VERSION "FL_CH_CANFD"

NS_ :

BS_:

BU_: ACU ADCC APA EGS EPS ESP FLZCU ONEBOX RXCU

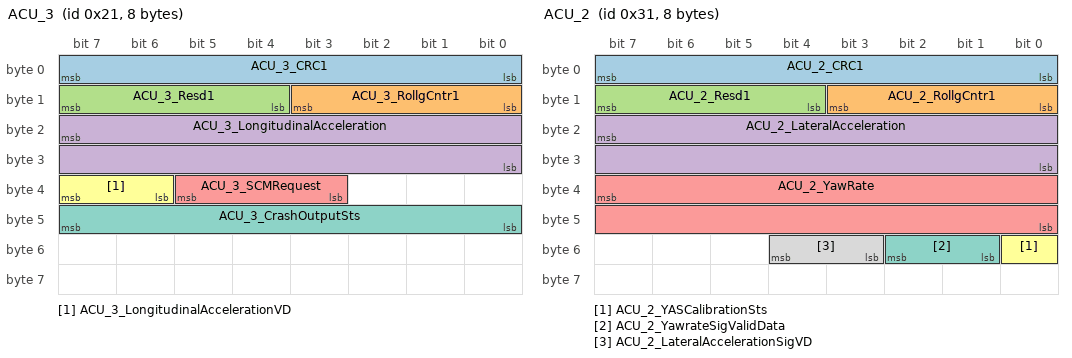
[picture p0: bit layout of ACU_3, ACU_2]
BO_ 33 ACU_3: 8 ACU
 SG_ ACU_3_CRC1 : 7|8@0+ (1,0) [0|255] "" RXCU
 SG_ ACU_3_RollgCntr1 : 11|4@0+ (1,0) [0|14] "" RXCU
 SG_ ACU_3_Resd1 : 15|4@0+ (1,0) [0|15] "" RXCU
 SG_ ACU_3_LongitudinalAcceleration : 23|16@0+ (0.001,-2) [-2|2] "g" RXCU
 SG_ ACU_3_SCMRequest : 37|3@0+ (1,0) [0|7] "" RXCU
 SG_ ACU_3_LongitudinalAccelerationVD : 39|2@0+ (1,0) [0|3] "" RXCU
 SG_ ACU_3_CrashOutputSts : 47|8@0+ (1,0) [0|255] "" RXCU

BO_ 49 ACU_2: 8 ACU
 SG_ ACU_2_CRC1 : 7|8@0+ (1,0) [0|255] "" RXCU
 SG_ ACU_2_RollgCntr1 : 11|4@0+ (1,0) [0|14] "" RXCU
 SG_ ACU_2_Resd1 : 15|4@0+ (1,0) [0|15] "" RXCU
 SG_ ACU_2_LateralAcceleration : 23|16@0+ (0.001,-2) [-2|2] "g" RXCU
 SG_ ACU_2_YawRate : 39|16@0+ (0.01,-180) [-180|180] "deg/sec" RXCU
 SG_ ACU_2_YASCalibrationSts : 48|1@0+ (1,0) [0|1] "" RXCU
 SG_ ACU_2_YawrateSigValidData : 50|2@0+ (1,0) [0|3] "" RXCU
 SG_ ACU_2_LateralAccelerationSigVD : 52|2@0+ (1,0) [0|3] "" RXCU

BO_ 56 VCU_COM_10: 16 RXCU
 SG_ VCU_10_CRC : 7|8@0+ (1,0) [0|255] "" ADCC,APA,FLZCU,ONEBOX
 SG_ VCU_10_RollgCntr : 11|4@0+ (1,0) [0|14] "" ADCC,APA,FLZCU,ONEBOX
 SG_ VCU_10_Resd : 15|4@0+ (1,0) [0|15] "" ADCC,APA,FLZCU,ONEBOX
 SG_ VCU_10_ShiftInProgress : 16|1@0+ (1,0) [0|1] "" ADCC,APA,FLZCU,ONEBOX
 SG_ VCU_10_ShiftInProgressValidData : 17|1@0+ (1,0) [0|1] "" ADCC,APA,FLZCU,ONEBOX
 SG_ VCU_10_TargetGear : 20|3@0+ (1,0) [0|7] "" ADCC,APA,FLZCU,ONEBOX
 SG_ VCU_10_ActualGear : 23|3@0+ (1,0) [0|7] "" ADCC,APA,FLZCU,ONEBOX
 SG_ VCU_10_TargetGearValidData : 28|1@0+ (1,0) [0|1] "" ADCC,APA,FLZCU,ONEBOX
 SG_ VCU_10_ActualGearValidData : 29|1@0+ (1,0) [0|1] "" ADCC,APA,FLZCU,ONEBOX
 SG_ VCU_10_BrakePedalStsValidData : 30|1@0+ (1,0) [0|1] "" ADCC,APA,FLZCU
 SG_ VCU_10_BrakePedalSts : 31|1@0+ (1,0) [0|1] "" ADCC,APA,FLZCU
 SG_ VCU_10_TowingMode : 49|2@0+ (1,0) [0|3] "" ADCC,APA,FLZCU,ONEBOX
 SG_ HCU_TCUR_GearShiftProgFlag : 63|2@0+ (1,0) [0|3] "" FLZCU,ONEBOX
 SG_ VCU_10_CRC2 : 71|8@0+ (1,0) [0|255] "" FLZCU
 SG_ VCU_10_RollgCntr2 : 75|4@0+ (1,0) [0|14] "" FLZCU
 SG_ VCU_10_Resd2 : 79|4@0+ (1,0) [0|15] "" FLZCU

BO_ 59 VCU_ONEBOX_11: 64 RXCU
 SG_ VCU_11_CRC1 : 7|8@0+ (1,0) [0|255] "" ADCC,APA,EPS,FLZCU,ONEBOX
 SG_ VCU_11_RollgCntr1 : 11|4@0+ (1,0) [0|14] "" ADCC,APA,EPS,FLZCU,ONEBOX
 SG_ VCU_11_Resd1 : 15|4@0+ (1,0) [0|15] "" ADCC,APA,EPS,FLZCU,ONEBOX
 SG_ VCU_11_IndicatedDriverReqWhlTqFA : 23|16@0+ (1,-32768) [-32768|32767] "NM" ADCC,APA,EPS,FLZCU,ONEBOX
 SG_ VCU_11_ActWheelTorqueFA : 39|16@0+ (1,-32768) [-32768|32767] "NM" ADCC,APA,EPS,FLZCU,ONEBOX
 SG_ VCU_11_ActWheelSpdFA : 55|16@0+ (1,-32767) [-32767|32767] "RPM" ADCC,APA,EPS,FLZCU,ONEBOX
 SG_ VCU_11_CRC2 : 71|8@0+ (1,0) [0|255] "" ADCC,APA,EPS,FLZCU,ONEBOX
 SG_ VCU_11_RollgCntr2 : 75|4@0+ (1,0) [0|14] "" ADCC,APA,EPS,FLZCU,ONEBOX
 SG_ VCU_11_Resd2 : 79|4@0+ (1,0) [0|15] "" ADCC,APA,EPS,FLZCU,ONEBOX
 SG_ VCU_11_IndcdDriverReqWhlTqStsFA : 80|1@0+ (1,0) [0|1] "" ADCC,APA,FLZCU,ONEBOX
 SG_ VCU_11_ActWheelTorqueStsFA : 82|2@0+ (1,0) [0|3] "" ADCC,APA,EPS,FLZCU,ONEBOX
 SG_ VCU_11_ActWheelSpdStsFA : 83|1@0+ (1,0) [0|1] "" ADCC,APA,EPS,FLZCU,ONEBOX
 SG_ VCU_11_MotorReadyFMCU : 84|1@0+ (1,0) [0|1] "" ADCC,APA,FLZCU,ONEBOX
 SG_ VCU_11_IndicatedDriverReqWhlTqRA : 95|16@0+ (1,-32768) [-32768|32767] "NM" ADCC,APA,FLZCU,ONEBOX
 SG_ VCU_11_ActWheelTorqueRA : 111|16@0+ (1,-32768) [-32768|32767] "NM" ADCC,APA,FLZCU,ONEBOX
 SG_ VCU_11_CRC3 : 135|8@0+ (1,0) [0|255] "" ADCC,APA,FLZCU,ONEBOX
 SG_ VCU_11_RollgCntr3 : 139|4@0+ (1,0) [0|14] "" ADCC,APA,FLZCU,ONEBOX
 SG_ VCU_11_Resd3 : 143|4@0+ (1,0) [0|15] "" ADCC,APA,FLZCU,ONEBOX
 SG_ VCU_11_ActWheelSpdRA : 151|16@0+ (1,-32767) [-32767|32767] "RPM" ADCC,APA,FLZCU,ONEBOX
 SG_ VCU_11_IndcdDriverReqWhlTqStsRA : 160|1@0+ (1,0) [0|1] "" ADCC,APA,FLZCU,ONEBOX
 SG_ VCU_11_ActWheelTorqueStsRA : 162|2@0+ (1,0) [0|3] "" ADCC,APA,FLZCU,ONEBOX
 SG_ VCU_11_MotorReadyRMCU : 163|1@0+ (1,0) [0|1] "" ADCC,APA,FLZCU,ONEBOX
 SG_ VCU_11_ActWheelSpdStsRA : 164|1@0+ (1,0) [0|1] "" ADCC,APA,FLZCU,ONEBOX
 SG_ VCU_11_MbRegenMaxWheel : 175|16@0+ (1,-32768) [-32768|32767] "NM" ADCC,APA,FLZCU,ONEBOX
 SG_ VCU_11_CRC4 : 199|8@0+ (1,0) [0|255] "" ADCC,APA,FLZCU,ONEBOX
 SG_ VCU_11_RollgCntr4 : 203|4@0+ (1,0) [0|14] "" ADCC,APA,FLZCU,ONEBOX
 SG_ VCU_11_Resd4 : 207|4@0+ (1,0) [0|15] "" ADCC,APA,FLZCU,ONEBOX
 SG_ VCU_11_MbRegenWheel : 215|16@0+ (1,-32768) [-32768|32767] "NM" ADCC,APA,FLZCU,ONEBOX
 SG_ VCU_11_MbRegenMaxWheelQualifier : 225|2@0+ (1,0) [0|3] "" ADCC,APA,FLZCU,ONEBOX
 SG_ VCU_11_MbRegenWheelQualifier : 227|2@0+ (1,0) [0|3] "" ADCC,APA,FLZCU,ONEBOX
 SG_ VCU_11_EPBReq : 229|2@0+ (1,0) [0|3] "" ADCC,APA,FLZCU,ONEBOX
 SG_ VCU_11_GasPedalPosInvalidData : 230|1@0+ (1,0) [0|1] "" ADCC,APA,FLZCU,ONEBOX
 SG_ VCU_11_AcceleratorPosRawIVD : 231|1@0+ (1,0) [0|1] "" ADCC,APA,FLZCU,ONEBOX
 SG_ VCU_11_GasPedalPosition : 239|10@0+ (0.1,0) [0|100] "%" ADCC,APA,FLZCU,ONEBOX
 SG_ VCU_11_AcceleratorPosRaw : 245|10@0+ (0.1,0) [0|100] "%" ADCC,APA,FLZCU,ONEBOX
 SG_ VCU_11_EPBReqValid : 251|1@0+ (1,0) [0|1] "" ADCC,APA,FLZCU,ONEBOX
 SG_ VCU_11_CRC5 : 263|8@0+ (1,0) [0|255] "" ADCC,APA,FLZCU
 SG_ VCU_11_RollgCntr5 : 267|4@0+ (1,0) [0|14] "" ADCC,APA,FLZCU
 SG_ VCU_11_Resd5 : 271|4@0+ (1,0) [0|15] "" ADCC,APA,FLZCU
 SG_ VCU_11_CoastRegenTargetWheelFA : 279|16@0+ (1,-32768) [-32768|32767] "NM" ADCC,APA,FLZCU,ONEBOX
 SG_ VCU_11_CoastRegenTargetWheelFAQ : 295|2@0+ (1,0) [0|3] "" ADCC,APA,FLZCU,ONEBOX
 SG_ VCU_11_CoastRegenTargetWheelRA : 303|16@0+ (1,-32768) [-32768|32767] "NM" ADCC,APA,FLZCU,ONEBOX
 SG_ VCU_11_CoastRegenTargetWheelRAQ : 319|2@0+ (1,0) [0|3] "" ADCC,APA,FLZCU,ONEBOX
 SG_ VCU_11_CRC6 : 327|8@0+ (1,0) [0|255] "" ADCC,APA,FLZCU
 SG_ VCU_11_RollgCntr6 : 331|4@0+ (1,0) [0|14] "" ADCC,APA,FLZCU
 SG_ VCU_11_Resd6 : 335|4@0+ (1,0) [0|15] "" ADCC,APA,FLZCU
 SG_ VCU_11_MaxWheelTorqueFA : 343|16@0+ (1,-32768) [-32768|32767] "NM" ADCC,APA,FLZCU,ONEBOX
 SG_ VCU_11_MaxWheelTorqueRA : 359|16@0+ (1,-32768) [-32768|32767] "NM" ADCC,APA,FLZCU,ONEBOX
 SG_ HCU_11_iTASRearTorque_Max : 375|16@0+ (1,-12000) [-12000|12000] "Nm" APA,FLZCU,ONEBOX
 SG_ VCU_11_CRC7 : 391|8@0+ (1,0) [0|255] "" ADCC,APA,FLZCU
 SG_ VCU_11_RollgCntr7 : 395|4@0+ (1,0) [0|14] "" ADCC,APA,FLZCU
 SG_ VCU_11_Resd7 : 399|4@0+ (1,0) [0|15] "" ADCC,APA,FLZCU
 SG_ VCU_11_OPDHoldRequest : 405|2@0+ (1,0) [0|3] "" ADCC,APA,FLZCU,ONEBOX
 SG_ VCU_11_OPDHydBrkCompenRqSts : 406|1@0+ (1,0) [0|1] "" ADCC,APA,FLZCU,ONEBOX
 SG_ VCU_11_OnePedalstatus : 407|1@0+ (1,0) [0|1] "" ADCC,APA,FLZCU,ONEBOX
 SG_ VCU_11_OPDHydBrkCompenRqTq : 415|16@0+ (1,-65535) [-65535|0] "NM" ADCC,APA,FLZCU,ONEBOX
 SG_ HCU_11_RearWheelDir : 426|2@0+ (1,0) [0|3] "" FLZCU,ONEBOX
 SG_ VCU_11_DrivingModReq : 431|5@0+ (1,0) [0|31] "" FLZCU,ONEBOX
 SG_ HCU_11_iTASFrontTorque_Max : 439|16@0+ (1,-12000) [-12000|12000] "Nm" FLZCU,ONEBOX
 SG_ VCU_11_CRC8 : 455|8@0+ (1,0) [0|255] "" ADCC,FLZCU
 SG_ VCU_11_RollgCntr8 : 459|4@0+ (1,0) [0|14] "" ADCC,FLZCU
 SG_ VCU_11_Resd8 : 463|4@0+ (1,0) [0|15] "" ADCC,FLZCU

BO_ 75 VCU_ADCC_12: 24 RXCU
 SG_ VCU_12_CRC1 : 7|8@0+ (1,0) [0|255] "" ADCC,APA,FLZCU,ONEBOX
 SG_ VCU_12_RollgCntr1 : 11|4@0+ (1,0) [0|14] "" ADCC,APA,FLZCU,ONEBOX
 SG_ VCU_12_Resd1 : 15|4@0+ (1,0) [0|15] "" ADCC,APA,FLZCU,ONEBOX
 SG_ VCU_12_DriverTorqueDesired : 23|16@0+ (1,-32768) [-32768|32767] "NM" ADCC,APA,FLZCU
 SG_ VCU_12_VehWhlActTq : 39|16@0+ (1,-32768) [-32768|32767] "NM" ADCC,APA,FLZCU,ONEBOX
 SG_ VCU_12_VehWhlActTqVld : 48|1@0+ (1,0) [0|1] "" ADCC,APA,FLZCU
 SG_ VCU_12_DrvrGearIntervention : 49|1@0+ (1,0) [0|1] "" ADCC,APA,FLZCU
 SG_ VCU_12_PtTqActvSts : 50|1@0+ (1,0) [0|1] "" ADCC,APA,FLZCU
 SG_ VCU_12_PtTqAvl : 52|2@0+ (1,0) [0|3] "" ADCC,APA,FLZCU
 SG_ VCU_12_DrvrAccrPedlOvrd : 53|1@0+ (1,0) [0|1] "" ADCC,APA,FLZCU
 SG_ VCU_12_DrvrAccrPedlOvrdInVD : 54|1@0+ (1,0) [0|1] "" ADCC,APA,FLZCU
 SG_ VCU_12_CRC2 : 71|8@0+ (1,0) [0|255] "" ADCC,APA,FLZCU
 SG_ VCU_12_RollgCntr2 : 75|4@0+ (1,0) [0|14] "" ADCC,APA,FLZCU
 SG_ VCU_12_Resd2 : 79|4@0+ (1,0) [0|15] "" ADCC,APA,FLZCU
 SG_ VCU_12_PtTqMax : 87|16@0+ (1,-32768) [-32768|32767] "NM" ADCC,APA,FLZCU
 SG_ HCU_12_PtTqMinVld : 96|1@0+ (1,0) [0|1] "" ADCC,APA,FLZCU
 SG_ TargetGearTransInp : 100|3@0+ (1,0) [0|7] "" ADCC,FLZCU
 SG_ VCU_12_GasPedalInhabition : 101|1@0+ (1,0) [0|1] "" ADCC,APA,FLZCU
 SG_ VCU_12_PtTqMaxVld : 103|1@0+ (1,0) [0|1] "" ADCC,APA,FLZCU
 SG_ HCU_12_PtTqMin : 111|16@0+ (1,-32768) [-32768|32767] "NM" ADCC,APA,FLZCU
 SG_ HCU_26_TargetGearEM2 : 127|2@0+ (1,0) [0|3] "" ADCC,FLZCU
 SG_ VCU_12_CRC3 : 135|8@0+ (1,0) [0|255] "" ADCC,APA,FLZCU
 SG_ VCU_12_RollgCntr3 : 139|4@0+ (1,0) [0|14] "" ADCC,APA,FLZCU
 SG_ VCU_12_Resd3 : 143|4@0+ (1,0) [0|15] "" ADCC,APA,FLZCU
 SG_ VCU_12_VehWhlActTqADS : 151|16@0+ (1,0) [0|65535] "NM" ADCC,APA,FLZCU
 SG_ VCU_12_VehWhlActTqADSVld : 167|1@0+ (1,0) [0|1] "" ADCC,APA,FLZCU

BO_ 152 ONEBOX_1: 24 ESP
 SG_ ONEBOX_1_CRC1 : 7|8@0+ (1,0) [0|255] "" RXCU
 SG_ ONEBOX_1_RollgCntr1 : 11|4@0+ (1,0) [0|14] "" RXCU
 SG_ ONEBOX_1_Resd1 : 15|4@0+ (1,0) [0|15] "" RXCU
 SG_ ABS_ESP_1_VehicleSpeedVSOSig : 23|13@0+ (0.0625,0) [0|511.875] "km/h" RXCU
 SG_ ABS_ESP_1_ABSFailSts : 24|1@0+ (1,0) [0|1] "" RXCU
 SG_ ABS_ESP_1_EBDFailSts : 25|1@0+ (1,0) [0|1] "" RXCU
 SG_ ESP1_VehicleSpeedVSOSigValidData : 26|1@0+ (1,0) [0|1] "" RXCU
 SG_ ONEBOX_1_IPB_SimulatorPressure : 39|10@0+ (1,0) [0|1022] "Bar" RXCU
 SG_ IPB_SimulatorPressureSts : 40|1@0+ (1,0) [0|1] "" RXCU
 SG_ ABS_ESP_1_ABSActive : 41|1@0+ (1,0) [0|1] "" RXCU
 SG_ ABS_ESP_1_VDCFailSts : 42|1@0+ (1,0) [0|1] "" RXCU
 SG_ ABS_ESP_1_VDCActive : 43|1@0+ (1,0) [0|1] "" RXCU
 SG_ ABS_ESP_1_TCSFailSts : 44|1@0+ (1,0) [0|1] "" RXCU
 SG_ ABS_ESP_1_TCSActive : 45|1@0+ (1,0) [0|1] "" RXCU
 SG_ BrakeSystemType : 48|1@0+ (1,0) [0|1] "" RXCU
 SG_ ABS_ESP_1_HHCFailSts : 49|1@0+ (1,0) [0|1] "" RXCU
 SG_ ONEBOX_1_HHCActive : 50|1@0+ (1,0) [0|1] "" RXCU
 SG_ ABS_ESP_1_HDCCtrlSts : 52|2@0+ (1,0) [0|3] "" RXCU
 SG_ ABS_ESP_1_HDCFailSts : 53|1@0+ (1,0) [0|1] "" RXCU
 SG_ ONEBOX_1_HLRequest : 54|1@0+ (1,0) [0|1] "" RXCU
 SG_ ABS_ESP_1_ESPSwitchStatus : 55|1@0+ (1,0) [0|1] "" RXCU
 SG_ ONEBOX_1_BLRequestController : 56|1@0+ (1,0) [0|1] "" RXCU
 SG_ SwitchOffCruiseControl : 57|1@0+ (1,0) [0|1] "" RXCU
 SG_ ONEBOX_1_CRC2 : 71|8@0+ (1,0) [0|255] "" RXCU
 SG_ ONEBOX_1_RollgCntr2 : 75|4@0+ (1,0) [0|14] "" RXCU
 SG_ ONEBOX_1_Resd2 : 79|4@0+ (1,0) [0|15] "" RXCU
 SG_ IPB_1_MbRegenTargetWheel : 87|16@0+ (1,-32768) [-32768|32767] "NM" RXCU
 SG_ IPB_1_MbRegenTargetWheelQ : 97|2@0+ (1,0) [0|3] "" RXCU
 SG_ ONEBOX_1_AEBdecActive : 98|1@0+ (1,0) [0|1] "" RXCU
 SG_ ONEBOX_1_AEBdecAvailable : 99|1@0+ (1,0) [0|1] "" RXCU
 SG_ ONEBOX_1_CDPActive : 100|1@0+ (1,0) [0|1] "" RXCU
 SG_ Reserve_EPBStatus : 103|3@0+ (1,0) [0|7] "" RXCU
 SG_ ONEBOX_1_CDPFailSts : 104|1@0+ (1,0) [0|1] "" RXCU
 SG_ ONEBOX_1_CRC3 : 135|8@0+ (1,0) [0|255] "" RXCU
 SG_ ONEBOX_1_RollgCntr3 : 139|4@0+ (1,0) [0|14] "" RXCU
 SG_ ONEBOX_1_Resd3 : 143|4@0+ (1,0) [0|15] "" RXCU

BO_ 168 ONEBOX_2: 24 ESP
 SG_ ONEBOX_2_CRC1 : 7|8@0+ (1,0) [0|255] "" RXCU
 SG_ ONEBOX_2_RollgCntr1 : 11|4@0+ (1,0) [0|14] "" RXCU
 SG_ ONEBOX_2_Resd1 : 15|4@0+ (1,0) [0|15] "" RXCU
 SG_ LHFWheelSpeed_0A8h : 23|13@0+ (0.0625,0) [0|511.875] "km/h" RXCU
 SG_ LHFWheelSpeedValidData_0A8h : 26|1@0+ (1,0) [0|1] "" RXCU
 SG_ RHFWheelSpeed_0A8h : 39|13@0+ (0.0625,0) [0|511.875] "km/h" RXCU
 SG_ RHFWheelSpeedValidData_0A8h : 42|1@0+ (1,0) [0|1] "" RXCU
 SG_ LHRWheelSpeed_0A8h : 55|13@0+ (0.0625,0) [0|511.875] "km/h" RXCU
 SG_ LHRWheelSpeedValidData_0A8h : 58|1@0+ (1,0) [0|1] "" RXCU
 SG_ ONEBOX_2_CRC2 : 71|8@0+ (1,0) [0|255] "" RXCU
 SG_ ONEBOX_2_RollgCntr2 : 75|4@0+ (1,0) [0|14] "" RXCU
 SG_ ONEBOX_2_Resd2 : 79|4@0+ (1,0) [0|15] "" RXCU
 SG_ RHRWheelSpeed_0A8h : 87|13@0+ (0.0625,0) [0|511.875] "km/h" RXCU
 SG_ RHRWheelSpeedValidData_0A8h : 90|1@0+ (1,0) [0|1] "" RXCU
 SG_ LHFWheelSpeedRPM : 103|16@0+ (0.0625,0) [0|4095.875] "rpm" RXCU
 SG_ RHFWheelSpeedRPM : 119|16@0+ (0.0625,0) [0|4095.875] "rpm" RXCU
 SG_ ONEBOX_2_CRC3 : 135|8@0+ (1,0) [0|255] "" RXCU
 SG_ ONEBOX_2_RollgCntr3 : 139|4@0+ (1,0) [0|14] "" RXCU
 SG_ ONEBOX_2_Resd3 : 143|4@0+ (1,0) [0|15] "" RXCU
 SG_ LHRWheelSpeedRPM_0A8h : 151|16@0+ (0.0625,0) [0|4095.875] "rpm" RXCU
 SG_ RHRWheelSpeedRPM_0A8h : 167|16@0+ (0.0625,0) [0|4095.875] "rpm" RXCU
 SG_ RHFWheelSpeedRPMValidData : 176|1@0+ (1,0) [0|1] "" RXCU
 SG_ LHFWheelSpeedRPMValidData : 177|1@0+ (1,0) [0|1] "" RXCU
 SG_ RHFWheelDriveDirection_0A8h : 180|3@0+ (1,0) [0|7] "" RXCU
 SG_ LHFWheelDriveDirection_0A8h : 183|3@0+ (1,0) [0|7] "" RXCU
 SG_ RHRWheelSpeedRPMValidData : 184|1@0+ (1,0) [0|1] "" RXCU
 SG_ LHRWheelSpeedRPMValidData : 185|1@0+ (1,0) [0|1] "" RXCU
 SG_ RHRWheelDriveDirection_0A8h : 188|3@0+ (1,0) [0|7] "" RXCU
 SG_ LHRWheelDriveDirection_0A8h : 191|3@0+ (1,0) [0|7] "" RXCU

BO_ 265 ONEBOX_HW_109h: 48 ONEBOX
 SG_ ONEBOX_CRC1_109h : 7|8@0+ (1,0) [0|255] "" RXCU
 SG_ ONEBOX_RollgCntr1_109h : 11|4@0+ (1,0) [0|14] "" RXCU
 SG_ ONEBOX_Resd1_109h : 15|4@0+ (1,0) [0|15] "" RXCU
 SG_ ONEBOX_AebBrkTqAvl_109h : 16|1@0+ (1,0) [0|1] "" RXCU
 SG_ ONEBOX_AebBrkTqActv_109h : 31|1@0+ (1,0) [0|1] "" RXCU
 SG_ ONEBOX_DrvrBrkOvrdVld_109h : 40|1@0+ (1,0) [0|1] "" RXCU
 SG_ ONEBOX_DrvrBrkOvrd_109h : 42|2@0+ (1,0) [0|3] "" RXCU

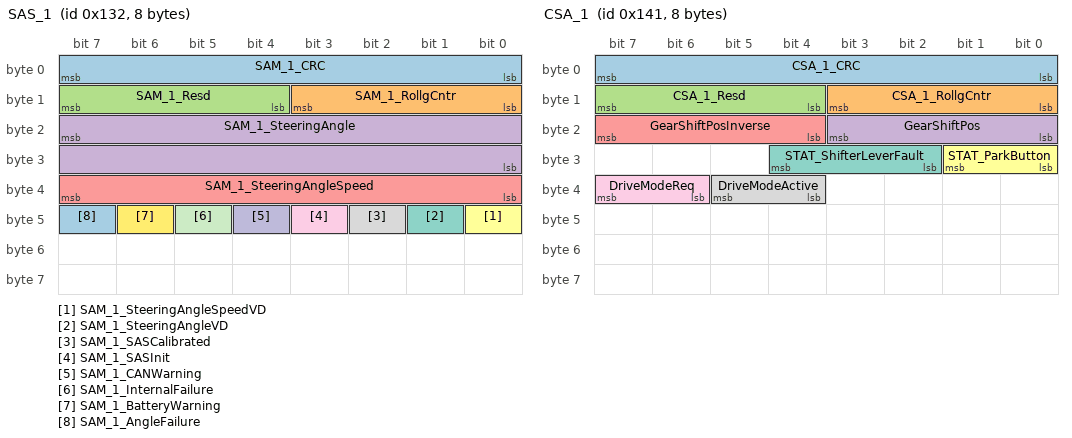
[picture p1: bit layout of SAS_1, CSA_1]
BO_ 306 SAS_1: 8 EPS
 SG_ SAM_1_CRC : 7|8@0+ (1,0) [0|255] "" RXCU
 SG_ SAM_1_RollgCntr : 11|4@0+ (1,0) [0|14] "" RXCU
 SG_ SAM_1_Resd : 15|4@0+ (1,0) [0|15] "" RXCU
 SG_ SAM_1_SteeringAngle : 23|16@0+ (0.0625,-2048) [-2048|2047.875] "deg" RXCU
 SG_ SAM_1_SteeringAngleSpeed : 39|8@0+ (4,0) [0|1016] "deg/Sec" RXCU
 SG_ SAM_1_SteeringAngleSpeedVD : 40|1@0+ (1,0) [0|1] "" RXCU
 SG_ SAM_1_SteeringAngleVD : 41|1@0+ (1,0) [0|1] "" RXCU
 SG_ SAM_1_SASCalibrated : 42|1@0+ (1,0) [0|1] "" RXCU
 SG_ SAM_1_SASInit : 43|1@0+ (1,0) [0|1] "" RXCU
 SG_ SAM_1_CANWarning : 44|1@0+ (1,0) [0|1] "" RXCU
 SG_ SAM_1_InternalFailure : 45|1@0+ (1,0) [0|1] "" RXCU
 SG_ SAM_1_BatteryWarning : 46|1@0+ (1,0) [0|1] "" RXCU
 SG_ SAM_1_AngleFailure : 47|1@0+ (1,0) [0|1] "" RXCU

BO_ 321 CSA_1: 8 EGS
 SG_ CSA_1_CRC : 7|8@0+ (1,0) [0|255] "" RXCU
 SG_ CSA_1_RollgCntr : 11|4@0+ (1,0) [0|14] "" RXCU
 SG_ CSA_1_Resd : 15|4@0+ (1,0) [0|15] "" RXCU
 SG_ GearShiftPos : 19|4@0+ (1,0) [0|15] "" RXCU
 SG_ GearShiftPosInverse : 23|4@0+ (1,0) [0|15] "" RXCU
 SG_ STAT_ParkButton : 25|2@0+ (1,0) [0|3] "" RXCU
 SG_ STAT_ShifterLeverFault : 28|3@0+ (1,0) [0|7] "" RXCU
 SG_ DriveModeActive : 37|2@0+ (1,0) [0|3] "" RXCU
 SG_ DriveModeReq : 39|2@0+ (1,0) [0|3] "" RXCU

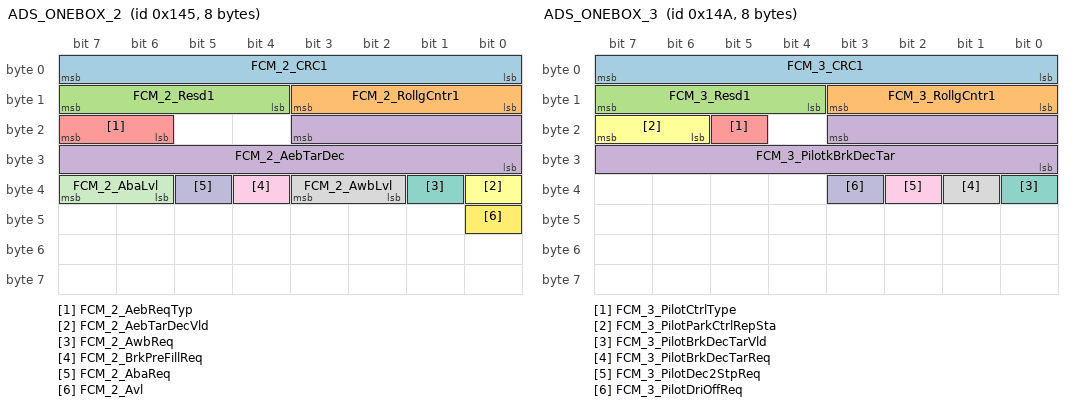
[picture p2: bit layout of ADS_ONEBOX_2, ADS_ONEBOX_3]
BO_ 325 ADS_ONEBOX_2: 8 ADCC
 SG_ FCM_2_CRC1 : 7|8@0+ (1,0) [0|255] "" RXCU
 SG_ FCM_2_RollgCntr1 : 11|4@0+ (1,0) [0|14] "" RXCU
 SG_ FCM_2_Resd1 : 15|4@0+ (1,0) [0|15] "" RXCU
 SG_ FCM_2_AebTarDec : 19|12@0+ (0.01,-20) [-20|0] "m/s2" RXCU
 SG_ FCM_2_AebReqTyp : 23|2@0+ (1,0) [0|3] "" RXCU
 SG_ FCM_2_AebTarDecVld : 32|1@0+ (1,0) [0|1] "" RXCU
 SG_ FCM_2_AwbReq : 33|1@0+ (1,0) [0|1] "" RXCU
 SG_ FCM_2_AwbLvl : 35|2@0+ (1,0) [0|3] "" RXCU
 SG_ FCM_2_BrkPreFillReq : 36|1@0+ (1,0) [0|1] "" RXCU
 SG_ FCM_2_AbaReq : 37|1@0+ (1,0) [0|1] "" RXCU
 SG_ FCM_2_AbaLvl : 39|2@0+ (1,0) [0|3] "" RXCU
 SG_ FCM_2_Avl : 40|1@0+ (1,0) [0|1] "" RXCU

BO_ 330 ADS_ONEBOX_3: 8 ADCC
 SG_ FCM_3_CRC1 : 7|8@0+ (1,0) [0|255] "" RXCU
 SG_ FCM_3_RollgCntr1 : 11|4@0+ (1,0) [0|14] "" RXCU
 SG_ FCM_3_Resd1 : 15|4@0+ (1,0) [0|15] "" RXCU
 SG_ FCM_3_PilotkBrkDecTar : 19|12@0+ (0.01,-20) [-20|20] "m/s2" RXCU
 SG_ FCM_3_PilotCtrlType : 21|1@0+ (1,0) [0|1] "" RXCU
 SG_ FCM_3_PilotParkCtrlRepSta : 23|2@0+ (1,0) [0|3] "" RXCU
 SG_ FCM_3_PilotBrkDecTarVld : 32|1@0+ (1,0) [0|1] "" RXCU
 SG_ FCM_3_PilotBrkDecTarReq : 33|1@0+ (1,0) [0|1] "" RXCU
 SG_ FCM_3_PilotDec2StpReq : 34|1@0+ (1,0) [0|1] "" RXCU
 SG_ FCM_3_PilotDriOffReq : 35|1@0+ (1,0) [0|1] "" RXCU

BO_ 335 ONEBOX_5: 24 ESP
 SG_ ONEBOX_5_CRC1 : 7|8@0+ (1,0) [0|255] "" RXCU
 SG_ ONEBOX_5_RollgCntr1 : 11|4@0+ (1,0) [0|14] "" RXCU
 SG_ ONEBOX_5_Resd1 : 15|4@0+ (1,0) [0|15] "" RXCU
 SG_ ONEBOX_5_PilotParkBrkDecCtlAvl : 16|1@0+ (1,0) [0|1] "" RXCU
 SG_ ONEBOX_5_PilotParkBrkDecActSts : 18|2@0+ (1,0) [0|3] "" RXCU
 SG_ ONEBOX_5_CddAdcActiveVehHld : 19|1@0+ (1,0) [0|1] "" RXCU
 SG_ ONEBOX_5_APCFailureSts : 23|4@0+ (1,0) [0|15] "" RXCU
 SG_ ONEBOX_5_APCStatus : 26|3@0+ (1,0) [0|7] "" RXCU
 SG_ ONEBOX_5_ApaAvl : 27|1@0+ (1,0) [0|1] "" RXCU
 SG_ ONEBOX_5_RpaAvl : 28|1@0+ (1,0) [0|1] "" RXCU
 SG_ ONEBOX_5_MebAvl : 29|1@0+ (1,0) [0|1] "" RXCU
 SG_ ONEBOX_5_CddApActiveVehHld : 30|1@0+ (1,0) [0|1] "" RXCU
 SG_ ONEBOX_5_SysBrkP : 39|10@0+ (1,0) [0|1022] "Bar" RXCU
 SG_ ONEBOX_5_SysBrkPVld : 40|1@0+ (1,0) [0|1] "" RXCU
 SG_ ONEBOX_5_AbpActSts : 41|1@0+ (1,0) [0|1] "" RXCU
 SG_ ONEBOX_5_AbpAvlSts : 42|1@0+ (1,0) [0|1] "" RXCU
 SG_ ONEBOX_5_AwbActSts : 43|1@0+ (1,0) [0|1] "" RXCU
 SG_ ONEBOX_5_AwbAvlSts : 44|1@0+ (1,0) [0|1] "" RXCU
 SG_ ONEBOX_5_AbaActSts : 45|1@0+ (1,0) [0|1] "" RXCU
 SG_ ONEBOX_5_AbaAvlSts : 48|1@0+ (1,0) [0|1] "" RXCU
 SG_ ONEBOX_5_AbaLvlSts : 50|2@0+ (1,0) [0|3] "" RXCU
 SG_ ONEBOX_5_CRC2 : 71|8@0+ (1,0) [0|255] "" RXCU
 SG_ ONEBOX_5_RollgCntr2 : 75|4@0+ (1,0) [0|14] "" RXCU
 SG_ ONEBOX_5_Resd2 : 79|4@0+ (1,0) [0|15] "" RXCU
 SG_ ONEBOX_5_OPDHydAvalible : 80|1@0+ (1,0) [0|1] "" RXCU
 SG_ ONEBOX_5_CoastRegenQualify_FA : 82|2@0+ (1,0) [0|3] "" RXCU
 SG_ ONEBOX_5_OPDHydBrkActvCompenTqVD : 83|1@0+ (1,0) [0|1] "" RXCU
 SG_ ONEBOX_5_OPDHoldStatus : 84|1@0+ (1,0) [0|1] "" RXCU
 SG_ ONEBOX_5_VehicleStandstillValid : 85|1@0+ (1,0) [0|1] "" RXCU
 SG_ ONEBOX_5_VehicleStandstill : 86|1@0+ (1,0) [0|1] "" RXCU
 SG_ ONEBOX_5_OPDHydBrkActvCompenTq : 95|16@0+ (1,-65535) [-65535|0] "NM" RXCU
 SG_ ONEBOX_5_OmpEngTorqReq : 111|16@0+ (1,-32768) [-32768|32767] "Nm" RXCU
 SG_ ONEBOX_5_OmpStatus : 125|2@0+ (1,0) [0|3] "" RXCU
 SG_ ONEBOX_5_OmpEngTorqReqEna : 127|2@0+ (1,0) [0|3] "" RXCU

BO_ 345 ADS_ONEBOX_1: 16 ADCC
 SG_ ADS_1_CRC1 : 7|8@0+ (1,0) [0|255] "" RXCU
 SG_ ADS_1_RollgCntr1 : 11|4@0+ (1,0) [0|14] "" RXCU
 SG_ ADS_1_Resd1 : 15|4@0+ (1,0) [0|15] "" RXCU
 SG_ ADS_1_PilotParkBrkDecTar : 19|12@0+ (0.01,-20) [-20|20] "m/s2" RXCU
 SG_ ADS_1_PilotParkCtrlType : 21|1@0+ (1,0) [0|1] "" RXCU
 SG_ ADS_1_PilotCtrlRepSta : 23|2@0+ (1,0) [0|3] "" RXCU
 SG_ ADS_1_PilotParkCtrlRepMod : 33|2@0+ (1,0) [0|3] "" RXCU
 SG_ ADS_1_PilotParkBrkDecTarVld : 34|1@0+ (1,0) [0|1] "" RXCU
 SG_ ADS_1_PilotParkBrkDecTarEnable : 35|1@0+ (1,0) [0|1] "" RXCU
 SG_ ADS_1_PilotParkDec2StpReq : 36|1@0+ (1,0) [0|1] "" RXCU
 SG_ ADS_1_PilotParkDriOffReq : 37|1@0+ (1,0) [0|1] "" RXCU
 SG_ ADS_1_StopDist : 47|16@0+ (1,0) [0|65535] "mm" RXCU
 SG_ ADS_1_ParkCtrlMod : 58|3@0+ (1,0) [0|7] "" RXCU
 SG_ ADS_1_PreFillReq : 59|1@0+ (1,0) [0|1] "" RXCU
 SG_ ADS_EPBCtrlReqValid : 60|1@0+ (1,0) [0|1] "" RXCU
 SG_ ADS_EPBCtrlReq : 62|2@0+ (1,0) [0|3] "" RXCU

BO_ 359 ADS_VCU_1: 16 ADCC
 SG_ ADS_VCU_1_CRC1 : 7|8@0+ (1,0) [0|255] "" RXCU
 SG_ ADS_VCU_1_RollgCntr1 : 11|4@0+ (1,0) [0|14] "" RXCU
 SG_ ADS_VCU_1_Resd1 : 15|4@0+ (1,0) [0|15] "" RXCU
 SG_ ADS_VCU_1_DrvTarTq : 23|16@0+ (1,-1000) [-1000|64535] "NM" RXCU
 SG_ ADS_VCU_1_DrvTarTqVld : 32|1@0+ (1,0) [0|1] "" RXCU
 SG_ ADS_VCU_1_DrvCtrlReq : 34|2@0+ (1,0) [0|3] "" RXCU
 SG_ ADS_VCU_1_CtrlReqMod : 36|2@0+ (1,0) [0|3] "" RXCU
 SG_ ADS_VCU_1_DrvTarTqEnable : 37|1@0+ (1,0) [0|1] "" RXCU
 SG_ ADS_VCU_1_AMAPRequest : 38|1@0+ (1,0) [0|1] "" RXCU
 SG_ ADS_VCU_1_AMAPRequestVld : 39|1@0+ (1,0) [0|1] "" RXCU
 SG_ ADS_VCU_1_ADCCAvl : 40|1@0+ (1,0) [0|1] "" RXCU
 SG_ ADS_VCU_1_AMAPTqLimitVld : 41|1@0+ (1,0) [0|1] "" RXCU
 SG_ FCM_FRM2_ACCStartStopInfo_167h : 61|2@0+ (1,0) [0|3] "" RXCU
 SG_ ADS_VCU_1_CRC2 : 71|8@0+ (1,0) [0|255] "" RXCU
 SG_ ADS_VCU_1_RollgCntr2 : 75|4@0+ (1,0) [0|14] "" RXCU
 SG_ ADS_VCU_1_Resd2 : 79|4@0+ (1,0) [0|15] "" RXCU
 SG_ ADS_VCU_1_TarGearReq : 82|3@0+ (1,0) [0|7] "" RXCU
 SG_ ADS_VCU_1_TarGearReqVld : 83|1@0+ (1,0) [0|1] "" RXCU
 SG_ ADS_VCU_1_GearCtrlEnable : 85|1@0+ (1,0) [0|1] "" RXCU
 SG_ ADS_VCU_1_RpaPTReadyReq : 86|1@0+ (1,0) [0|1] "" RXCU
 SG_ ADS_VCU_1_AMAPTqLimit : 103|12@0+ (1,0) [0|4000] "NM" RXCU

BO_ 363 ADS_HW_16Bh: 64 ADCC
 SG_ ADS_CRC2_16Bh : 71|8@0+ (1,0) [0|255] "" RXCU
 SG_ ADS_RollgCntr2_16Bh : 75|4@0+ (1,0) [0|14] "" RXCU
 SG_ ADS_Resd2_16Bh : 79|4@0+ (1,0) [0|15] "" RXCU
 SG_ ADS_TarYawRate_16Bh : 119|16@0+ (0.01,-163.84) [-163.84|167.67] "deg/s" RXCU

BO_ 364 ADS_HW_16Ch: 48 ADCC
 SG_ ADS_CRC1_16Ch : 7|8@0+ (1,0) [0|255] "" RXCU
 SG_ ADS_RollgCntr1_16Ch : 11|4@0+ (1,0) [0|14] "" RXCU
 SG_ ADS_Resd1_16Ch : 15|4@0+ (1,0) [0|15] "" RXCU
 SG_ ADS_DrvTarTq_16Ch : 23|16@0+ (1,-32768) [-32768|32767] "Nm" RXCU
 SG_ ADS_LimTqFactorK_16Ch : 33|10@0+ (0.001,0) [0|1.023] "" RXCU
 SG_ ADS_LimTqEnable_16Ch : 34|1@0+ (1,0) [0|1] "" RXCU
 SG_ ADS_DrvTarTqMod_16Ch : 36|2@0+ (1,0) [0|3] "" RXCU
 SG_ ADS_DrvTarTqEna_16Ch : 37|1@0+ (1,0) [0|1] "" RXCU
 SG_ ADS_DrvTarTqVld_16Ch : 39|2@0+ (1,0) [0|3] "" RXCU
 SG_ ADS_Total_Ref_Torque_16Ch : 55|16@0+ (1,-32768) [-32768|32767] "Nm" RXCU
 SG_ ADS_CRC2_16Ch : 71|8@0+ (1,0) [0|255] "" RXCU
 SG_ ADS_RollgCntr2_16Ch : 75|4@0+ (1,0) [0|14] "" RXCU
 SG_ ADS_Resd2_16Ch : 79|4@0+ (1,0) [0|15] "" RXCU
 SG_ ADS_FctSts_16Ch : 80|1@0+ (1,0) [0|1] "" RXCU
 SG_ ADS_GearCtrlEna_16Ch : 81|1@0+ (1,0) [0|1] "" RXCU
 SG_ ADS_TarGearReqVld_16Ch : 83|2@0+ (1,0) [0|3] "" RXCU
 SG_ ADS_TarGearReq_16Ch : 86|3@0+ (1,0) [0|7] "" RXCU
 SG_ ADS_RapidRespEna_16Ch : 87|1@0+ (1,0) [0|1] "" RXCU
 SG_ ADS_MotTarSpd_16Ch : 95|16@0+ (1,-32768) [-32768|32767] "rpm" RXCU
 SG_ ADS_MotTqLimMin_16Ch : 106|9@0+ (25,-6375) [-6375|6400] "Nm" RXCU
 SG_ ADS_MotTarMod_16Ch : 108|2@0+ (1,0) [0|3] "" RXCU
 SG_ ADS_MotCtrlTar_16Ch : 111|3@0+ (1,0) [0|7] "" RXCU
 SG_ ADS_MotTqLimMax_16Ch : 113|9@0+ (25,-6375) [-6375|6400] "Nm" RXCU
 SG_ ADS_MotSpdCtrlEna_16Ch : 120|1@0+ (1,0) [0|1] "" RXCU
 SG_ ADS_CRC3_16Ch : 135|8@0+ (1,0) [0|255] "" RXCU
 SG_ ADS_RollgCntr3_16Ch : 139|4@0+ (1,0) [0|14] "" RXCU
 SG_ ADS_Resd3_16Ch : 143|4@0+ (1,0) [0|15] "" RXCU
 SG_ ADS_MotTqRateLimMin_16Ch : 151|9@0+ (50,-12750) [-12750|12800] "Nm/s" RXCU
 SG_ ADS_MotTqRateLimMax_16Ch : 158|9@0+ (50,-12750) [-12750|12800] "Nm/s" RXCU
 SG_ ADS_TqUnloadRate_16Ch : 163|9@0+ (50,-12750) [-12750|12800] "Nm/s" RXCU
 SG_ ADS_TqUnloadEna_16Ch : 165|2@0+ (1,0) [0|3] "" RXCU
 SG_ ADS_TarYawRateVld_16Ch : 169|1@0+ (1,0) [0|1] "" RXCU
 SG_ ADS_MotTarSpdSvValid_16Ch : 170|1@0+ (1,0) [0|1] "" RXCU
 SG_ ADS_DrvTarYawMom_16Ch : 183|16@0+ (1,-32768) [-32768|32767] "Nm" RXCU
 SG_ ADS_CRC4_16Ch : 199|8@0+ (1,0) [0|255] "" RXCU
 SG_ ADS_RollgCntr4_16Ch : 203|4@0+ (1,0) [0|14] "" RXCU
 SG_ ADS_Resd4_16Ch : 207|4@0+ (1,0) [0|15] "" RXCU
 SG_ ADS_OneMotorCtrlEn_16Ch : 209|2@0+ (1,0) [0|3] "" RXCU
 SG_ ADS_UrgentSteerFlg_16Ch : 210|1@0+ (1,0) [0|1] "" RXCU
 SG_ ADS_DrvYawMomCtrlEna_16Ch : 211|1@0+ (1,0) [0|1] "" RXCU
 SG_ ADS_DrvTarYawMomVld_16Ch : 212|1@0+ (1,0) [0|1] "" RXCU
 SG_ ADS_PwrOnOffReq_16Ch : 215|3@0+ (1,0) [0|7] "" RXCU
 SG_ ADS_MotorCtrlTqWhlFL_16Ch : 223|16@0+ (1,-32768) [-32768|32767] "Nm" RXCU
 SG_ ADS_MotorCtrlTqWhlFR_16Ch : 239|16@0+ (1,-32768) [-32768|32767] "Nm" RXCU
 SG_ ADS_CRC5_16Ch : 263|8@0+ (1,0) [0|255] "" RXCU
 SG_ ADS_RollgCntr5_16Ch : 267|4@0+ (1,0) [0|14] "" RXCU
 SG_ ADS_Resd5_16Ch : 271|4@0+ (1,0) [0|15] "" RXCU
 SG_ ADS_MotorCtrlTqWhlRL_16Ch : 279|16@0+ (1,-32768) [-32768|32767] "Nm" RXCU
 SG_ ADS_MotorCtrlTqWhlRR_16Ch : 295|16@0+ (1,-32768) [-32768|32767] "Nm" RXCU
 SG_ ADS_CRC6_16Ch : 327|8@0+ (1,0) [0|255] "" RXCU
 SG_ ADS_RollgCntr6_16Ch : 331|4@0+ (1,0) [0|14] "" RXCU
 SG_ ADS_Resd6_16Ch : 335|4@0+ (1,0) [0|15] "" RXCU

BO_ 444 ADS_EPS_3: 24 ADCC
 SG_ ADS_CRC1_1BCh : 7|8@0+ (1,0) [0|255] "" RXCU
 SG_ ADS_RollgCntr1 : 11|4@0+ (1,0) [0|14] "" RXCU
 SG_ ADS_Resd1_1BCh : 15|4@0+ (1,0) [0|15] "" RXCU
 SG_ ADS_CRC2_1BCh : 71|8@0+ (1,0) [0|255] "" RXCU
 SG_ ADS_RollgCntr2_1BCh : 75|4@0+ (1,0) [0|14] "" RXCU
 SG_ ADS_Resd2_1BCh : 79|4@0+ (1,0) [0|15] "" RXCU
 SG_ APA_DrvTarTqVld_1BCh : 80|1@0+ (1,0) [0|1] "" RXCU
 SG_ DrvTarTq_1BCh : 95|16@0+ (1,-1000) [-1000|64535] "mm" RXCU
 SG_ APA_EPBCtrlReq_1BCh : 105|2@0+ (1,0) [0|3] "" RXCU
 SG_ APA_DrvCtrlReq_1BCh : 107|2@0+ (1,0) [0|3] "" RXCU
 SG_ APA_CtrlReqMod_1BCh : 109|2@0+ (1,0) [0|3] "" RXCU
 SG_ APA_AMAPTqLimit_1BCh : 119|10@0+ (1,0) [0|1023] "NM" RXCU
 SG_ APA_TarGearReqVld_1BCh : 121|1@0+ (1,0) [0|1] "" RXCU
 SG_ APA_TarGearReq_1BCh : 124|3@0+ (1,0) [0|7] "" RXCU
 SG_ APA_AMAPTqLimitVld_1BCh : 125|1@0+ (1,0) [0|1] "" RXCU
 SG_ APA_CRC3_1BCh : 135|8@0+ (1,0) [0|255] "" RXCU
 SG_ APA_RollgCntr3_1BCh : 139|4@0+ (1,0) [0|14] "" RXCU
 SG_ APA_Resd3_1BCh : 143|4@0+ (1,0) [0|15] "" RXCU
 SG_ APA_TarSpd_1BCh : 146|7@0+ (0.1,0) [0|10] "km/h" RXCU
 SG_ APA_ParkCtrlMod_1BCh : 149|3@0+ (1,0) [0|7] "" RXCU
 SG_ APA_GearCtrlEnable_1BCh : 150|1@0+ (1,0) [0|1] "" RXCU
 SG_ APA_EPBCtrlReqValid_1BCh : 151|1@0+ (1,0) [0|1] "" RXCU
 SG_ APA_ADCCAvl_1BCh : 152|1@0+ (1,0) [0|1] "" RXCU
 SG_ APA_AMAPRequestVld_1BCh : 153|1@0+ (1,0) [0|1] "" RXCU
 SG_ APA_AMAPRequest_1BCh : 154|1@0+ (1,0) [0|1] "" RXCU
 SG_ APA_DrvTarTqEnable_1BCh : 155|1@0+ (1,0) [0|1] "" RXCU

BO_TX_BU_ 152 : ESP,ONEBOX;
BO_TX_BU_ 168 : ESP,ONEBOX;
BO_TX_BU_ 325 : ADCC,FLZCU;
BO_TX_BU_ 330 : ADCC,FLZCU;
BO_TX_BU_ 335 : ESP,ONEBOX;
BO_TX_BU_ 345 : ADCC,APA;
BO_TX_BU_ 359 : ADCC,FLZCU;
BO_TX_BU_ 444 : ADCC,APA;

CM_ BO_ 325 "非华为智驾：FCM与ADCC共用此帧信号华为智驾：此帧报文删除";
CM_ BO_ 330 "非华为智驾：非冗余配置，此帧信号在低配发送，中配不发送；冗余配置，此帧信号与0x159为冗余关系；华为智驾：此帧报文删除";
CM_ BO_ 359 "国内高配ADCC在CH发此信号，低配DA_FCM发，国际DA_FRM发";
CM_ BO_ 363 "华为MDC新增";
CM_ BO_ 364 "华为MDC新增";
CM_ SG_ 33 ACU_3_CRC1 "Profile1A:E2E CRC (SAE J1850 CRC-8) for 8 Bytes
DataID:0x0002";
CM_ SG_ 33 ACU_3_RollgCntr1 "Profile1A:E2E Rolling message counter(the maximum value of Alive counter is 14)";
CM_ SG_ 33 ACU_3_Resd1 "Profile1A:E2E Reserved";
CM_ SG_ 33 ACU_3_LongitudinalAcceleration "纵向加速度
Longitudinal acceleration signal
Sensor accuracy：0.0027680342857143 g";
CM_ SG_ 33 ACU_3_SCMRequest "二次碰撞预警(D01不做)默认发0
SCM:Second Collision Mitigate
For front crash,deceleration limitation is -5, The Maximum rate of Deceleration for Non-Front(Side and Rear) crash in the platform is maximum? (-14 M/S^2) in full brake system, the deceleration limitation is ASIL B related, should discussed by project specific.
此信号发到ECU停止工作为止";
CM_ SG_ 33 ACU_3_LongitudinalAccelerationVD "纵向加速度有效位
If hasn’t been calibrated, after initialization, this signal ‘s value is always10(invalid)";
CM_ SG_ 33 ACU_3_CrashOutputSts "碰撞状态信号
Crash signal indicates the status according to bit:
If multiple directions collide at the same time, each collision flag bit representing each direction will be set to 1.For example, if left crash is superimposed with right crash, the output signal is 00001100
此信号发到ECU停止工作为止";
CM_ SG_ 49 ACU_2_CRC1 "Profile1A:E2E CRC (SAE J1850 CRC-8) for 8 Bytes
DataID:0x0001";
CM_ SG_ 49 ACU_2_RollgCntr1 "Profile1A:E2E Rolling message counter(the maximum value of Alive counter is 14)";
CM_ SG_ 49 ACU_2_Resd1 "Profile1A:E2E Reserved";
CM_ SG_ 49 ACU_2_LateralAcceleration "横向加速度
Lateral acceleration signal
Sensor accuracy：0.0027680342857143g";
CM_ SG_ 49 ACU_2_YawRate "偏航角速度
Yaw rate signal
Sensor accuracy：0.122189236 deg/s";
CM_ SG_ 49 ACU_2_YASCalibrationSts "YAS标定状态
Indicates  IMU Calibration State";
CM_ SG_ 49 ACU_2_YawrateSigValidData "偏航角速度有效性
Signal state for yawrate";
CM_ SG_ 49 ACU_2_LateralAccelerationSigVD "横向加速度有效性
If hasn’t been calibrated, after initialization, this signal ‘s value is always 10(invalid).";
CM_ SG_ 56 VCU_10_CRC "Profile1A:E2E CRC (SAE J1850 CRC-8) for 8 Bytes
DataID:0x0068";
CM_ SG_ 56 VCU_10_RollgCntr "Profile1A:E2E Rolling message counter(the maximum value of Alive counter is 14)";
CM_ SG_ 56 VCU_10_Resd "Profile1A:E2E Reserved";
CM_ SG_ 56 VCU_10_ShiftInProgress "shifting progress judgement";
CM_ SG_ 56 VCU_10_ShiftInProgressValidData "shifting progress judgement validation";
CM_ SG_ 56 VCU_10_TargetGear "目标档位
Target gear";
CM_ SG_ 56 VCU_10_ActualGear "实际档位
actual gear";
CM_ SG_ 56 VCU_10_TargetGearValidData "目标档位有效性
valid Target gear";
CM_ SG_ 56 VCU_10_ActualGearValidData "实际档位有效性
valid actual gear";
CM_ SG_ 56 VCU_10_BrakePedalStsValidData "制动踏板状态有效";
CM_ SG_ 56 VCU_10_BrakePedalSts "制动踏板状态";
CM_ SG_ 56 VCU_10_TowingMode "拖车模式";
CM_ SG_ 56 HCU_TCUR_GearShiftProgFlag "捷途新增RSCU相关换挡信号The shifting status of rear gearbox（ONEBOX接收）";
CM_ SG_ 56 VCU_10_CRC2 "Profile1A:E2E CRC (SAE J1850 CRC-8) for 8 Bytes
DataID:0x01BB";
CM_ SG_ 56 VCU_10_RollgCntr2 "Profile1A:E2E Rolling message counter(the maximum value of Alive counter is 14)";
CM_ SG_ 56 VCU_10_Resd2 "Profile1A:E2E Reserved";
CM_ SG_ 59 VCU_11_CRC1 "Profile1A:E2E CRC (SAE J1850 CRC-8) for 8 Bytes
DataID:0x0069";
CM_ SG_ 59 VCU_11_RollgCntr1 "Profile1A:E2E Rolling message counter(the maximum value of Alive counter is 14)";
CM_ SG_ 59 VCU_11_Resd1 "Profile1A:E2E Reserved";
CM_ SG_ 59 VCU_11_IndicatedDriverReqWhlTqFA "前轴需求轮端扭矩
Driver request wheel torque at FA";
CM_ SG_ 59 VCU_11_ActWheelTorqueFA "前轴实际轮端扭矩
Actual wheel torque at FA";
CM_ SG_ 59 VCU_11_ActWheelSpdFA "前轮转速（基于电机转速计算）
The motor terminal speed, forward and backward are both sent the positive value";
CM_ SG_ 59 VCU_11_CRC2 "Profile1A:E2E CRC (SAE J1850 CRC-8) for 8 Bytes
DataID:0x006A";
CM_ SG_ 59 VCU_11_RollgCntr2 "Profile1A:E2E Rolling message counter(the maximum value of Alive counter is 14)";
CM_ SG_ 59 VCU_11_Resd2 "Profile1A:E2E Reserved";
CM_ SG_ 59 VCU_11_IndcdDriverReqWhlTqStsFA "前轴需求轮端扭矩有效
Driver request wheel torque status at FA";
CM_ SG_ 59 VCU_11_ActWheelTorqueStsFA "前轴实际轮端扭矩有效
Actual wheel torque status at FA";
CM_ SG_ 59 VCU_11_ActWheelSpdStsFA "前轮转速有效
Actual wheel speed status at FA";
CM_ SG_ 59 VCU_11_MotorReadyFMCU "When the high voltage power-on of the motor is complete and there is no fault, 'Ready' will be sent, other conditions,'Not Ready'will be sent";
CM_ SG_ 59 VCU_11_IndicatedDriverReqWhlTqRA "后轴需求轮端扭矩
Driver request wheel torque at RA";
CM_ SG_ 59 VCU_11_ActWheelTorqueRA "后轴实际轮端扭矩
Actual wheel torque at RA";
CM_ SG_ 59 VCU_11_CRC3 "Profile1A:E2E CRC (SAE J1850 CRC-8) for 8 Bytes
DataID:0x006B";
CM_ SG_ 59 VCU_11_RollgCntr3 "Profile1A:E2E Rolling message counter(the maximum value of Alive counter is 14)";
CM_ SG_ 59 VCU_11_Resd3 "Profile1A:E2E Reserved";
CM_ SG_ 59 VCU_11_ActWheelSpdRA "后轮转速（基于电机转速计算）
The motor terminal speed, forward and backward are both sent the positive value";
CM_ SG_ 59 VCU_11_IndcdDriverReqWhlTqStsRA "后轴需求轮端扭矩有效
Driver request wheel torque status at RA";
CM_ SG_ 59 VCU_11_ActWheelTorqueStsRA "后轴实际轮端扭矩有效
Actual wheel torque status at RA";
CM_ SG_ 59 VCU_11_MotorReadyRMCU "When the high voltage power-on of the motor is complete and there is no fault, 'Ready' will be sent, other conditions,'Not Ready'will be sent";
CM_ SG_ 59 VCU_11_ActWheelSpdStsRA "后轮转速有效
Actual wheel speed status at RA";
CM_ SG_ 59 VCU_11_MbRegenMaxWheel "Max regen torque potential";
CM_ SG_ 59 VCU_11_CRC4 "Profile1A:E2E CRC (SAE J1850 CRC-8) for 8 Bytes
DataID:0x006C";
CM_ SG_ 59 VCU_11_RollgCntr4 "Profile1A:E2E Rolling message counter(the maximum value of Alive counter is 14)";
CM_ SG_ 59 VCU_11_Resd4 "Profile1A:E2E Reserved";
CM_ SG_ 59 VCU_11_MbRegenWheel "Actual regen torque";
CM_ SG_ 59 VCU_11_MbRegenMaxWheelQualifier "Max regen torque potential status";
CM_ SG_ 59 VCU_11_MbRegenWheelQualifier "Actual regen torque status";
CM_ SG_ 59 VCU_11_EPBReq "VCU request EPB function";
CM_ SG_ 59 VCU_11_GasPedalPosition "Driver/Cruise control
This signal including compositive informations which are actual gas pedal position and dummy Cruise control gas pedal position";
CM_ SG_ 59 VCU_11_AcceleratorPosRaw "Raw position of the accelerator pedal (unfiltered). Represents always raw pedal position without any other influcence only mandatory to calculated gradient acceleration pedal.";
CM_ SG_ 59 VCU_11_CRC5 "Profile1A:E2E CRC (SAE J1850 CRC-8) for 8 Bytes
DataID:0x01B7";
CM_ SG_ 59 VCU_11_RollgCntr5 "Profile1A:E2E Rolling message counter(the maximum value of Alive counter is 14)";
CM_ SG_ 59 VCU_11_Resd5 "Profile1A:E2E Reserved";
CM_ SG_ 59 VCU_11_CoastRegenTargetWheelFA "Coast regen target torque at wheel";
CM_ SG_ 59 VCU_11_CoastRegenTargetWheelFAQ "Coast regen target torque status at wheel";
CM_ SG_ 59 VCU_11_CoastRegenTargetWheelRA "Coast regen target torque at wheel";
CM_ SG_ 59 VCU_11_CoastRegenTargetWheelRAQ "Coast regen target torque status at wheel";
CM_ SG_ 59 VCU_11_CRC6 "Profile1A:E2E CRC (SAE J1850 CRC-8) for 8 Bytes
DataID:0x01B6";
CM_ SG_ 59 VCU_11_RollgCntr6 "Profile1A:E2E Rolling message counter(the maximum value of Alive counter is 14)";
CM_ SG_ 59 VCU_11_Resd6 "Profile1A:E2E Reserved";
CM_ SG_ 59 HCU_11_iTASRearTorque_Max "iTAS功能HCU可提供后轴最大扭矩";
CM_ SG_ 59 VCU_11_CRC7 "Profile1A:E2E CRC (SAE J1850 CRC-8) for 8 Bytes
DataID:0x01B5";
CM_ SG_ 59 VCU_11_RollgCntr7 "Profile1A:E2E Rolling message counter(the maximum value of Alive counter is 14)";
CM_ SG_ 59 VCU_11_Resd7 "Profile1A:E2E Reserved";
CM_ SG_ 59 VCU_11_OPDHoldRequest "车辆静止状态请求";
CM_ SG_ 59 VCU_11_OPDHydBrkCompenRqSts "液压制动补偿请求状态";
CM_ SG_ 59 VCU_11_OnePedalstatus "单踏板模式开启状态（底盘专用）";
CM_ SG_ 59 VCU_11_OPDHydBrkCompenRqTq "液压制动补偿力矩";
CM_ SG_ 59 HCU_11_RearWheelDir "HCU反馈后轴扭矩方向";
CM_ SG_ 59 VCU_11_DrivingModReq "HCU给IPB映射驾驶模式";
CM_ SG_ 59 HCU_11_iTASFrontTorque_Max "iTAS功能HCU可提供前轴最大扭矩";
CM_ SG_ 59 VCU_11_CRC8 "Profile1A:E2E CRC (SAE J1850 CRC-8) for 8 Bytes
DataID:0x01B4";
CM_ SG_ 59 VCU_11_RollgCntr8 "Profile1A:E2E Rolling message counter(the maximum value of Alive counter is 14)";
CM_ SG_ 59 VCU_11_Resd8 "Profile1A:E2E Reserved";
CM_ SG_ 75 VCU_12_CRC1 "Profile1A:E2E CRC (SAE J1850 CRC-8) for 8 Bytes
DataID:0x006D";
CM_ SG_ 75 VCU_12_RollgCntr1 "Profile1A:E2E Rolling message counter(the maximum value of Alive counter is 14)";
CM_ SG_ 75 VCU_12_Resd1 "Profile1A:E2E Reserved";
CM_ SG_ 75 VCU_12_DriverTorqueDesired "Driver Torque Desieed";
CM_ SG_ 75 VCU_12_VehWhlActTq "实际总的轮端扭矩值反馈";
CM_ SG_ 75 VCU_12_VehWhlActTqVld "实际总的轮端扭矩值有效状态";
CM_ SG_ 75 VCU_12_DrvrGearIntervention "驾驶员档位干预状态
Driver Intervention Gear status";
CM_ SG_ 75 VCU_12_PtTqActvSts "VCU 扭矩响应反馈状态
VCU Torque Active State";
CM_ SG_ 75 VCU_12_PtTqAvl "动力系统扭矩可用状态
VCU PT Torque Available";
CM_ SG_ 75 VCU_12_DrvrAccrPedlOvrd "驾驶员加速踏板干预状态
Driver Accelerator Pedal Override";
CM_ SG_ 75 VCU_12_DrvrAccrPedlOvrdInVD "T1J FL2华为版新增DrvrAccrPedlOvrd有效位";
CM_ SG_ 75 VCU_12_CRC2 "Profile1A:E2E CRC (SAE J1850 CRC-8) for 8 Bytes
DataID:0x006E";
CM_ SG_ 75 VCU_12_RollgCntr2 "Profile1A:E2E Rolling message counter(the maximum value of Alive counter is 14)";
CM_ SG_ 75 VCU_12_Resd2 "Profile1A:E2E Reserved";
CM_ SG_ 75 VCU_12_PtTqMax "动力总成最大允许电动扭矩(驱动能力)
VCU PT Torque Max";
CM_ SG_ 75 HCU_12_PtTqMinVld "HCU PT Torque Min status";
CM_ SG_ 75 TargetGearTransInp "HCU给TCU发的目标档位";
CM_ SG_ 75 VCU_12_GasPedalInhabition "反馈加速踏板抑制状态
VCU Gas Pedal Inhabition";
CM_ SG_ 75 VCU_12_PtTqMaxVld "动力总成最大允许电动扭矩有效
VCU PT Torque Max status";
CM_ SG_ 75 HCU_12_PtTqMin "HCU PT Torque Min";
CM_ SG_ 75 HCU_26_TargetGearEM2 "Target gear for EM2";
CM_ SG_ 75 VCU_12_CRC3 "Profile1A:E2E CRC (SAE J1850 CRC-8) for 8 Bytes
DataID:0x006F";
CM_ SG_ 75 VCU_12_RollgCntr3 "Profile1A:E2E Rolling message counter(the maximum value of Alive counter is 14)";
CM_ SG_ 75 VCU_12_Resd3 "Profile1A:E2E Reserved";
CM_ SG_ 75 VCU_12_VehWhlActTqADS "实际响应ADS请求总的轮端扭矩值反馈";
CM_ SG_ 75 VCU_12_VehWhlActTqADSVld "实际响应ADS请求总的轮端扭矩值有效状态";
CM_ SG_ 152 ONEBOX_1_CRC1 "Profile1A:E2E CRC (SAE J1850 CRC-8) for 8 Bytes
DataID:0x0049";
CM_ SG_ 152 ONEBOX_1_RollgCntr1 "Profile1A:E2E Rolling message counter(the maximum value of Alive counter is 14)";
CM_ SG_ 152 ONEBOX_1_Resd1 "Profile1A:E2E Reserved";
CM_ SG_ 152 ABS_ESP_1_VehicleSpeedVSOSig "车速
Vehicle Speed";
CM_ SG_ 152 ABS_ESP_1_ABSFailSts "ABS Fail Status";
CM_ SG_ 152 ABS_ESP_1_EBDFailSts "EBD Fail Status";
CM_ SG_ 152 ESP1_VehicleSpeedVSOSigValidData "车速有效性
Valid check bit of the signal ABS_ESP_1_VehicleSpeedVSOSig";
CM_ SG_ 152 ONEBOX_1_IPB_SimulatorPressure "Indicate simulator pressure";
CM_ SG_ 152 IPB_SimulatorPressureSts "Valid check bit of the signal simulator pressure";
CM_ SG_ 152 ABS_ESP_1_ABSActive "ABS Active";
CM_ SG_ 152 ABS_ESP_1_VDCFailSts "VDC Fail Status";
CM_ SG_ 152 ABS_ESP_1_VDCActive "ESP lamp on ICM should blinking ;VDC Intervention";
CM_ SG_ 152 ABS_ESP_1_TCSFailSts "TCS Fail Status";
CM_ SG_ 152 ABS_ESP_1_TCSActive "ESP lamp on ICM should blinking; TCS Intervention";
CM_ SG_ 152 BrakeSystemType "Brake System Type";
CM_ SG_ 152 ABS_ESP_1_HHCFailSts "HHC Fail Sts";
CM_ SG_ 152 ONEBOX_1_HHCActive "HHC Active";
CM_ SG_ 152 ABS_ESP_1_HDCCtrlSts "HDC Control Sts";
CM_ SG_ 152 ABS_ESP_1_HDCFailSts "HDC Fail Sts";
CM_ SG_ 152 ONEBOX_1_HLRequest "HL Request";
CM_ SG_ 152 ABS_ESP_1_ESPSwitchStatus "“1” means VDC and Engine Traction Control System (PTC) Function and Brake Traction Control System (BTC) Function disabled and Ignit ESP lamp.";
CM_ SG_ 152 ONEBOX_1_BLRequestController "BL Request Controller";
CM_ SG_ 152 SwitchOffCruiseControl "Switch Off Cruise Control";
CM_ SG_ 152 ONEBOX_1_CRC2 "Profile1A:E2E CRC (SAE J1850 CRC-8) for 8 Bytes
DataID:0x004A";
CM_ SG_ 152 ONEBOX_1_RollgCntr2 "Profile1A:E2E Rolling message counter(the maximum value of Alive counter is 14)";
CM_ SG_ 152 ONEBOX_1_Resd2 "Profile1A:E2E Reserved";
CM_ SG_ 152 IPB_1_MbRegenTargetWheel "This Torque is vehicle axle level,not generator axle level.";
CM_ SG_ 152 ONEBOX_1_AEBdecActive "AEB  braking function";
CM_ SG_ 152 ONEBOX_1_AEBdecAvailable "AEB 可用";
CM_ SG_ 152 ONEBOX_1_CDPActive "CDP Active";
CM_ SG_ 152 Reserve_EPBStatus "EPB Status
手刹状态信号以0x264(EPB_1_ActrSt)信号为准，此信号改为预留不发。";
CM_ SG_ 152 ONEBOX_1_CDPFailSts "CDP Fail Status";
CM_ SG_ 152 ONEBOX_1_CRC3 "Profile1A:E2E CRC (SAE J1850 CRC-8) for 8 Bytes
DataID:0x01CB";
CM_ SG_ 152 ONEBOX_1_RollgCntr3 "Profile1A:E2E Rolling message counter(the maximum value of Alive counter is 14)";
CM_ SG_ 152 ONEBOX_1_Resd3 "Profile1A:E2E Reserved";
CM_ SG_ 168 ONEBOX_2_CRC1 "Profile1A:E2E CRC (SAE J1850 CRC-8) for 8 Bytes
DataID:0x004B";
CM_ SG_ 168 ONEBOX_2_RollgCntr1 "Profile1A:E2E Rolling message counter(the maximum value of Alive counter is 14)";
CM_ SG_ 168 ONEBOX_2_Resd1 "Profile1A:E2E Reserved";
CM_ SG_ 168 LHFWheelSpeed_0A8h "left front Wheel Speed";
CM_ SG_ 168 LHFWheelSpeedValidData_0A8h "Valid check bit of the signal LHFWheelSpeed";
CM_ SG_ 168 RHFWheelSpeed_0A8h "right front  Wheel Speed";
CM_ SG_ 168 RHFWheelSpeedValidData_0A8h "Valid check bit of the signal RHFWheelSpeed";
CM_ SG_ 168 LHRWheelSpeed_0A8h "Left Rear Wheel Speed";
CM_ SG_ 168 LHRWheelSpeedValidData_0A8h "Valid check bit of the signal LHRWheelSpeed";
CM_ SG_ 168 ONEBOX_2_CRC2 "Profile1A:E2E CRC (SAE J1850 CRC-8) for 8 Bytes
DataID:0x004C";
CM_ SG_ 168 ONEBOX_2_RollgCntr2 "Profile1A:E2E Rolling message counter(the maximum value of Alive counter is 14)";
CM_ SG_ 168 ONEBOX_2_Resd2 "Profile1A:E2E Reserved";
CM_ SG_ 168 RHRWheelSpeed_0A8h "Right Rear Wheel Speed";
CM_ SG_ 168 RHRWheelSpeedValidData_0A8h "Valid check bit of the signal RHRWheelSpeed";
CM_ SG_ 168 LHFWheelSpeedRPM "left front Wheel Speed(the unit is RPM)";
CM_ SG_ 168 RHFWheelSpeedRPM "right front  Wheel Speed(the unit is RPM)";
CM_ SG_ 168 ONEBOX_2_CRC3 "Profile1A:E2E CRC (SAE J1850 CRC-8) for 8 Bytes
DataID:0x00A1";
CM_ SG_ 168 ONEBOX_2_RollgCntr3 "Profile1A:E2E Rolling message counter(the maximum value of Alive counter is 14)";
CM_ SG_ 168 ONEBOX_2_Resd3 "Profile1A:E2E Reserved";
CM_ SG_ 168 LHRWheelSpeedRPM_0A8h "Left Rear Wheel Speed(the unit is RPM)";
CM_ SG_ 168 RHRWheelSpeedRPM_0A8h "right Rear  Wheel Speed(the unit is RPM)";
CM_ SG_ 168 RHFWheelSpeedRPMValidData "Valid check bit of the signal RHFWheelSpeedRPM";
CM_ SG_ 168 LHFWheelSpeedRPMValidData "Valid check bit of the signal LHFWheelSpeedRPM";
CM_ SG_ 168 RHFWheelDriveDirection_0A8h "right front Wheel Speed Drive Direction";
CM_ SG_ 168 LHFWheelDriveDirection_0A8h "left front Wheel Speed Drive Direction";
CM_ SG_ 168 RHRWheelSpeedRPMValidData "Valid check bit of the signal RHRWheelSpeedRPM";
CM_ SG_ 168 LHRWheelSpeedRPMValidData "Valid check bit of the signal LHRWheelSpeedRPM";
CM_ SG_ 168 RHRWheelDriveDirection_0A8h "right rear Wheel Speed Drive Direction";
CM_ SG_ 168 LHRWheelDriveDirection_0A8h "left rear Wheel Speed Drive Direction";
CM_ SG_ 265 ONEBOX_CRC1_109h "Profile1A:E2E CRC (SAE J1850 CRC-8) for 8 Bytes
DataID:0x01D8";
CM_ SG_ 265 ONEBOX_RollgCntr1_109h "Profile1A:E2E Rolling message counter(the maximum value of Alive counter is 14)";
CM_ SG_ 265 ONEBOX_Resd1_109h "Profile1A:E2E Reserved";
CM_ SG_ 265 ONEBOX_AebBrkTqAvl_109h "AEB力矩接口可用状态";
CM_ SG_ 265 ONEBOX_AebBrkTqActv_109h "AEB力矩接口响应状态";
CM_ SG_ 265 ONEBOX_DrvrBrkOvrdVld_109h "制动override状态有效位";
CM_ SG_ 265 ONEBOX_DrvrBrkOvrd_109h "制动override状态";
CM_ SG_ 306 SAM_1_CRC "Profile1A:E2E CRC (SAE J1850 CRC-8) for 8 Bytes
DataID:0x0035";
CM_ SG_ 306 SAM_1_RollgCntr "Profile1A:E2E Rolling message counter(the maximum value of Alive counter is 14)";
CM_ SG_ 306 SAM_1_Resd "Profile1A:E2E Reserved";
CM_ SG_ 306 SAM_1_SteeringAngle "方向盘转角角度值";
CM_ SG_ 306 SAM_1_SteeringAngleSpeed "方向盘转角角速度";
CM_ SG_ 306 SAM_1_SteeringAngleSpeedVD "角速度有效性";
CM_ SG_ 306 SAM_1_SteeringAngleVD "角度有效性";
CM_ SG_ 306 SAM_1_SASCalibrated "角度传感器标定状态";
CM_ SG_ 321 CSA_1_CRC "Profile1A:E2E CRC (SAE J1850 CRC-8) for 8 Bytes
DataID:0x0029";
CM_ SG_ 321 CSA_1_RollgCntr "Profile1A:E2E Rolling message counter(the maximum value of Alive counter is 14)";
CM_ SG_ 321 CSA_1_Resd "Profile1A:E2E Reserved";
CM_ SG_ 321 GearShiftPos "Driver requested gear shift position";
CM_ SG_ 321 GearShiftPosInverse "Driver requested gear shift position inverse";
CM_ SG_ 321 STAT_ParkButton "Driver Request Park Button";
CM_ SG_ 321 STAT_ShifterLeverFault "Shift sensor fault status";
CM_ SG_ 321 DriveModeActive "SBW decide whether enter into Sport Mode.
备注：E03国内、E0Y国内项目CSA不发";
CM_ SG_ 321 DriveModeReq "SBW transmit Sport Mode request.
备注：E03国内、E0Y国内项目CSA不发";
CM_ SG_ 325 FCM_2_CRC1 "Profile1A:E2E CRC (SAE J1850 CRC-8) for 8 Bytes
DataID:0x0009";
CM_ SG_ 325 FCM_2_RollgCntr1 "Profile1A:E2E Rolling message counter(the maximum value of Alive counter is 14)";
CM_ SG_ 325 FCM_2_Resd1 "Profile1A:E2E Reserved";
CM_ SG_ 325 FCM_2_AebTarDec "AEB目标减速度
AEB target deceleration";
CM_ SG_ 325 FCM_2_AebReqTyp "AEB紧急制动请求
Emergency brake request";
CM_ SG_ 325 FCM_2_AebTarDecVld "AEB目标减速度有效性
AEB target deceleration valid";
CM_ SG_ 325 FCM_2_AwbReq "AWB请求
AWB request";
CM_ SG_ 325 FCM_2_AwbLvl "AWB请求等级
AWB request level";
CM_ SG_ 325 FCM_2_BrkPreFillReq "ABP请求
ABP request";
CM_ SG_ 325 FCM_2_AbaReq "ABA 阈值请求
ABA request";
CM_ SG_ 325 FCM_2_AbaLvl "ABA 阈值等级
ABA request level";
CM_ SG_ 325 FCM_2_Avl "FCM Function State
FCM整体可用状态";
CM_ SG_ 330 FCM_3_CRC1 "Profile1A:E2E CRC (SAE J1850 CRC-8) for 8 Bytes
DataID:0x000A";
CM_ SG_ 330 FCM_3_RollgCntr1 "Profile1A:E2E Rolling message counter(the maximum value of Alive counter is 14)";
CM_ SG_ 330 FCM_3_Resd1 "Profile1A:E2E Reserved";
CM_ SG_ 330 FCM_3_PilotkBrkDecTar "Pilot target deceleration(-12~12m/s2)";
CM_ SG_ 330 FCM_3_PilotCtrlType "Pilot  control state";
CM_ SG_ 330 FCM_3_PilotParkCtrlRepSta "Pilot  Control Request";
CM_ SG_ 330 FCM_3_PilotBrkDecTarVld "Pilot target deceleration valid";
CM_ SG_ 330 FCM_3_PilotBrkDecTarReq "Pilot target deceleration enable";
CM_ SG_ 330 FCM_3_PilotDec2StpReq "Pilot  deceleration to stop request";
CM_ SG_ 330 FCM_3_PilotDriOffReq "Pilot drive off request";
CM_ SG_ 335 ONEBOX_5_CRC1 "Profile1A:E2E CRC (SAE J1850 CRC-8) for 8 Bytes
DataID:0x0055";
CM_ SG_ 335 ONEBOX_5_RollgCntr1 "Profile1A:E2E Rolling message counter(the maximum value of Alive counter is 14)";
CM_ SG_ 335 ONEBOX_5_Resd1 "Profile1A:E2E Reserved";
CM_ SG_ 335 ONEBOX_5_PilotParkBrkDecCtlAvl "行车减速度控制接口可用性
Pilot deceleration control interface available";
CM_ SG_ 335 ONEBOX_5_PilotParkBrkDecActSts "行车减速度控制响应状态
Pilot deceleration control status";
CM_ SG_ 335 ONEBOX_5_CddAdcActiveVehHld "Flag indicate that vehicle is actively hold by longitudinal actuator controller";
CM_ SG_ 335 ONEBOX_5_APCFailureSts "error status";
CM_ SG_ 335 ONEBOX_5_APCStatus "泊车纵向控制器状态
response park control status";
CM_ SG_ 335 ONEBOX_5_ApaAvl "表示 APA 可用于纵向控制
response APA available status";
CM_ SG_ 335 ONEBOX_5_RpaAvl "表示 RPA 可用于纵向控制(包括 HPA)
response RPA/AVP(include HPA) available status";
CM_ SG_ 335 ONEBOX_5_MebAvl "表示 PEB 可用状态
response MEB available status";
CM_ SG_ 335 ONEBOX_5_CddApActiveVehHld "Flag indicate that vehicle is actively hold by longitudinal actuator controller";
CM_ SG_ 335 ONEBOX_5_SysBrkP "Driver pedal pressure";
CM_ SG_ 335 ONEBOX_5_SysBrkPVld "Driver pedal pressure status";
CM_ SG_ 335 ONEBOX_5_AbpActSts "ABP 激活状态
ABP active status";
CM_ SG_ 335 ONEBOX_5_AbpAvlSts "ABP 有效状态
ABP available status";
CM_ SG_ 335 ONEBOX_5_AwbActSts "AWB 激活状态
AWB active status";
CM_ SG_ 335 ONEBOX_5_AwbAvlSts "AWB 有效状态
AWB available status";
CM_ SG_ 335 ONEBOX_5_AbaActSts "ABA 激活状态
ABA active status";
CM_ SG_ 335 ONEBOX_5_AbaAvlSts "ABA 有效状态
ABA available status";
CM_ SG_ 335 ONEBOX_5_AbaLvlSts "ABA 阈值等级
ABA level status";
CM_ SG_ 335 ONEBOX_5_CRC2 "Profile1A:E2E CRC (SAE J1850 CRC-8) for 8 Bytes
DataID:0x00B0";
CM_ SG_ 335 ONEBOX_5_RollgCntr2 "Profile1A:E2E Rolling message counter(the maximum value of Alive counter is 14)";
CM_ SG_ 335 ONEBOX_5_Resd2 "Profile1A:E2E Reserved";
CM_ SG_ 335 ONEBOX_5_OPDHydAvalible "单踏板IPB液压协控能力";
CM_ SG_ 335 ONEBOX_5_CoastRegenQualify_FA "Coast Regen torque control indication of front axle
前电机滑行能量回收控制能力（On状态，允许滑行能量回收，OFF状态，IPB不支持滑行能量回收）";
CM_ SG_ 335 ONEBOX_5_OPDHydBrkActvCompenTqVD "液压制动实际补偿力矩有效";
CM_ SG_ 335 ONEBOX_5_OPDHoldStatus "单踏板Hold状态";
CM_ SG_ 335 ONEBOX_5_VehicleStandstillValid "车辆静止有效";
CM_ SG_ 335 ONEBOX_5_VehicleStandstill "Indicating whether the vehicle is standstill or not; Cannot be set until standstill is surely reached
车辆静止";
CM_ SG_ 335 ONEBOX_5_OPDHydBrkActvCompenTq "液压制动实际补偿力矩";
CM_ SG_ 335 ONEBOX_5_OmpEngTorqReq "OMP扭矩请求值";
CM_ SG_ 335 ONEBOX_5_OmpStatus "OMP当前模块状态";
CM_ SG_ 335 ONEBOX_5_OmpEngTorqReqEna "OMP扭矩请求使能位";
CM_ SG_ 345 ADS_1_CRC1 "Profile1A:E2E CRC (SAE J1850 CRC-8) for 8 Bytes
DataID:0x0008";
CM_ SG_ 345 ADS_1_RollgCntr1 "Profile1A:E2E Rolling message counter(the maximum value of Alive counter is 14)";
CM_ SG_ 345 ADS_1_Resd1 "Profile1A:E2E Reserved";
CM_ SG_ 345 ADS_1_PilotParkBrkDecTar "行/泊车请求目标加速度
Pilot/Parkt target deceleration(-12~12m/s2)";
CM_ SG_ 345 ADS_1_PilotParkCtrlType "Park  control state
ADAS行/泊车减速控制类型";
CM_ SG_ 345 ADS_1_PilotCtrlRepSta "Pilot  Control Request
行车控制请求状态
L12代表智驾L1，L2等级";
CM_ SG_ 345 ADS_1_PilotParkCtrlRepMod "行/泊车控制请求模式
Pilot/Park control request mode";
CM_ SG_ 345 ADS_1_PilotParkBrkDecTarVld "行泊车减速请求有效性
Pilot/Park target deceleration valid";
CM_ SG_ 345 ADS_1_PilotParkBrkDecTarEnable "行泊车减速请求使能
Pilot/Park target deceleration enable";
CM_ SG_ 345 ADS_1_PilotParkDec2StpReq "行/泊车制动减速减速至停止请求
Pilot/Park  deceleration to stop request";
CM_ SG_ 345 ADS_1_PilotParkDriOffReq "行/泊车起步请求
Pilot/Park drive off request";
CM_ SG_ 345 ADS_1_StopDist "泊车停止距离
Parking distance request";
CM_ SG_ 345 ADS_1_ParkCtrlMod "泊车功能控制模式
Parking control mode request";
CM_ SG_ 345 ADS_1_PreFillReq "泊车预填充请求
Park PreFill request";
CM_ SG_ 345 ADS_EPBCtrlReqValid "EPB功能请求有效";
CM_ SG_ 345 ADS_EPBCtrlReq "EPB功能请求";
CM_ SG_ 359 ADS_VCU_1_CRC1 "Profile1A:E2E CRC (SAE J1850 CRC-8) for 8 Bytes
DataID:0x000B";
CM_ SG_ 359 ADS_VCU_1_RollgCntr1 "Profile1A:E2E Rolling message counter(the maximum value of Alive counter is 14)";
CM_ SG_ 359 ADS_VCU_1_Resd1 "Profile1A:E2E Reserved";
CM_ SG_ 359 ADS_VCU_1_DrvTarTq "ADS Drive traget torque  Request";
CM_ SG_ 359 ADS_VCU_1_DrvTarTqVld "ADS Drive traget torque  Request valid";
CM_ SG_ 359 ADS_VCU_1_DrvCtrlReq "ADS Drive Control Request";
CM_ SG_ 359 ADS_VCU_1_CtrlReqMod "ADS Drive Control Mode";
CM_ SG_ 359 ADS_VCU_1_DrvTarTqEnable "ADS Drive traget torque  Request enable";
CM_ SG_ 359 ADS_VCU_1_AMAPRequest "域控ADCC 踏板误加速使能信
号";
CM_ SG_ 359 ADS_VCU_1_AMAPRequestVld "域控ADCC 踏板误加速使能信
号有效值";
CM_ SG_ 359 ADS_VCU_1_ADCCAvl "ADCC Function State
ADCC整体可用状态";
CM_ SG_ 359 ADS_VCU_1_AMAPTqLimitVld "AMAP function limit Tq valid
踏板误加速功能限制扭矩范围有效位";
CM_ SG_ 359 FCM_FRM2_ACCStartStopInfo_167h "ACC对智能启停ISS需求";
CM_ SG_ 359 ADS_VCU_1_CRC2 "Profile1A:E2E CRC (SAE J1850 CRC-8) for 8 Bytes
DataID:0x000C";
CM_ SG_ 359 ADS_VCU_1_RollgCntr2 "Profile1A:E2E Rolling message counter(the maximum value of Alive counter is 14)";
CM_ SG_ 359 ADS_VCU_1_Resd2 "Profile1A:E2E Reserved";
CM_ SG_ 359 ADS_VCU_1_TarGearReq "ADS Target Gear Request";
CM_ SG_ 359 ADS_VCU_1_TarGearReqVld "ADS Target Gear Request Valid";
CM_ SG_ 359 ADS_VCU_1_GearCtrlEnable "ADS Gear Control Enable";
CM_ SG_ 359 ADS_VCU_1_RpaPTReadyReq "RPA功能用于PT ready保持的标识位";
CM_ SG_ 359 ADS_VCU_1_AMAPTqLimit "AMAP function limit Tq 
踏板误加速功能限制扭矩范围";
CM_ SG_ 363 ADS_CRC2_16Bh "Profile1A:E2E CRC (SAE J1850 CRC-8) for 8 Bytes
DataID:0x01CF";
CM_ SG_ 363 ADS_RollgCntr2_16Bh "Profile1A:E2E Rolling message counter(the maximum value of Alive counter is 14)";
CM_ SG_ 363 ADS_Resd2_16Bh "Profile1A:E2E Reserved";
CM_ SG_ 363 ADS_TarYawRate_16Bh "目标横摆";
CM_ SG_ 364 ADS_CRC1_16Ch "Profile1A:E2E CRC (SAE J1850 CRC-8) for 8 Bytes
DataID:0x01DC";
CM_ SG_ 364 ADS_RollgCntr1_16Ch "Profile1A:E2E Rolling message counter(the maximum value of Alive counter is 14)";
CM_ SG_ 364 ADS_Resd1_16Ch "Profile1A:E2E Reserved";
CM_ SG_ 364 ADS_DrvTarTq_16Ch "驱动目标扭矩";
CM_ SG_ 364 ADS_LimTqFactorK_16Ch "限扭系数";
CM_ SG_ 364 ADS_LimTqEnable_16Ch "ADS发送限扭使能信号";
CM_ SG_ 364 ADS_DrvTarTqMod_16Ch "驱动扭矩模式";
CM_ SG_ 364 ADS_DrvTarTqEna_16Ch "驱动目标扭矩使能";
CM_ SG_ 364 ADS_DrvTarTqVld_16Ch "驱动目标扭矩有效";
CM_ SG_ 364 ADS_Total_Ref_Torque_16Ch "ADS总参考扭矩，仅用于VCU进行override标志位判断";
CM_ SG_ 364 ADS_CRC2_16Ch "Profile1A:E2E CRC (SAE J1850 CRC-8) for 8 Bytes
DataID:0x01DB";
CM_ SG_ 364 ADS_RollgCntr2_16Ch "Profile1A:E2E Rolling message counter(the maximum value of Alive counter is 14)";
CM_ SG_ 364 ADS_Resd2_16Ch "Profile1A:E2E Reserved";
CM_ SG_ 364 ADS_FctSts_16Ch "智能驾驶功能激活状态";
CM_ SG_ 364 ADS_GearCtrlEna_16Ch "挡位控制使能";
CM_ SG_ 364 ADS_TarGearReqVld_16Ch "目标挡位请求有效";
CM_ SG_ 364 ADS_TarGearReq_16Ch "目标挡位";
CM_ SG_ 364 ADS_RapidRespEna_16Ch "ADS快速响应模式";
CM_ SG_ 364 ADS_MotTarSpd_16Ch "期望电机转速";
CM_ SG_ 364 ADS_MotTqLimMin_16Ch "轮端扭矩下限";
CM_ SG_ 364 ADS_MotTarMod_16Ch "电机目标模式";
CM_ SG_ 364 ADS_MotCtrlTar_16Ch "ADS期望控制目标电机";
CM_ SG_ 364 ADS_MotTqLimMax_16Ch "轮端扭矩上限";
CM_ SG_ 364 ADS_MotSpdCtrlEna_16Ch "转速模式控制使能";
CM_ SG_ 364 ADS_CRC3_16Ch "Profile1A:E2E CRC (SAE J1850 CRC-8) for 8 Bytes
DataID:0x01DA";
CM_ SG_ 364 ADS_RollgCntr3_16Ch "Profile1A:E2E Rolling message counter(the maximum value of Alive counter is 14)";
CM_ SG_ 364 ADS_Resd3_16Ch "Profile1A:E2E Reserved";
CM_ SG_ 364 ADS_MotTqRateLimMin_16Ch "轮端扭矩变化率下限";
CM_ SG_ 364 ADS_MotTqRateLimMax_16Ch "轮端扭矩变化率上限";
CM_ SG_ 364 ADS_TqUnloadRate_16Ch "轮端卸扭斜率";
CM_ SG_ 364 ADS_TqUnloadEna_16Ch "请求卸扭使能";
CM_ SG_ 364 ADS_TarYawRateVld_16Ch "差动驱动的目标横摆角速度请求有效位";
CM_ SG_ 364 ADS_MotTarSpdSvValid_16Ch "转速模式控制有效位";
CM_ SG_ 364 ADS_DrvTarYawMom_16Ch "ADS期望控制的差动驱动目标横摆力矩";
CM_ SG_ 364 ADS_CRC4_16Ch "Profile1A:E2E CRC (SAE J1850 CRC-8) for 8 Bytes
DataID:0x01C0";
CM_ SG_ 364 ADS_RollgCntr4_16Ch "Profile1A:E2E Rolling message counter(the maximum value of Alive counter is 14)";
CM_ SG_ 364 ADS_Resd4_16Ch "Profile1A:E2E Reserved";
CM_ SG_ 364 ADS_OneMotorCtrlEn_16Ch "直控电机扭矩使能";
CM_ SG_ 364 ADS_UrgentSteerFlg_16Ch "紧急转向标志位";
CM_ SG_ 364 ADS_DrvYawMomCtrlEna_16Ch "差动驱动的目标横摆力矩控制使能位";
CM_ SG_ 364 ADS_DrvTarYawMomVld_16Ch "差动驱动的目标横摆力矩请求有效位";
CM_ SG_ 364 ADS_PwrOnOffReq_16Ch "MDC泊车上下ready请求（备注：已在RPA页体现）";
CM_ SG_ 364 ADS_MotorCtrlTqWhlFL_16Ch "左前电机目标力矩";
CM_ SG_ 364 ADS_MotorCtrlTqWhlFR_16Ch "右前电机目标力矩";
CM_ SG_ 364 ADS_CRC5_16Ch "Profile1A:E2E CRC (SAE J1850 CRC-8) for 8 Bytes
DataID:0x01BF";
CM_ SG_ 364 ADS_RollgCntr5_16Ch "Profile1A:E2E Rolling message counter(the maximum value of Alive counter is 14)";
CM_ SG_ 364 ADS_Resd5_16Ch "Profile1A:E2E Reserved";
CM_ SG_ 364 ADS_MotorCtrlTqWhlRL_16Ch "左后电机目标力矩";
CM_ SG_ 364 ADS_MotorCtrlTqWhlRR_16Ch "右后电机目标力矩";
CM_ SG_ 364 ADS_CRC6_16Ch "Profile1A:E2E CRC (SAE J1850 CRC-8) for 8 Bytes
DataID:0x01BE";
CM_ SG_ 364 ADS_RollgCntr6_16Ch "Profile1A:E2E Rolling message counter(the maximum value of Alive counter is 14)";
CM_ SG_ 364 ADS_Resd6_16Ch "Profile1A:E2E Reserved";
CM_ SG_ 444 ADS_CRC1_1BCh "Profile1A:E2E CRC (SAE J1850 CRC-8) for 8 Bytes
DataID:0x0006";
CM_ SG_ 444 ADS_RollgCntr1 "Profile1A:E2E Rolling message counter(the maximum value of Alive counter is 14)";
CM_ SG_ 444 ADS_Resd1_1BCh "Profile1A:E2E Reserved";
CM_ SG_ 444 ADS_CRC2_1BCh "Profile1A:E2E CRC (SAE J1850 CRC-8) for 8 Bytes
DataID:0x0007";
CM_ SG_ 444 ADS_RollgCntr2_1BCh "Profile1A:E2E Rolling message counter(the maximum value of Alive counter is 14)";
CM_ SG_ 444 ADS_Resd2_1BCh "Profile1A:E2E Reserved";
CM_ SG_ 444 APA_DrvTarTqVld_1BCh "ADS Drive traget torque  Request valid";
CM_ SG_ 444 DrvTarTq_1BCh "ADS Drive traget torque  Request";
CM_ SG_ 444 APA_EPBCtrlReq_1BCh "EPB功能请求";
CM_ SG_ 444 APA_DrvCtrlReq_1BCh "ADS Drive Control Request";
CM_ SG_ 444 APA_CtrlReqMod_1BCh "ADS Drive Control Mode";
CM_ SG_ 444 APA_AMAPTqLimit_1BCh "AMAP function limit Tq 
踏板误加速功能限制扭矩范围";
CM_ SG_ 444 APA_TarGearReqVld_1BCh "ADS Target Gear Request Valid";
CM_ SG_ 444 APA_TarGearReq_1BCh "ADS Target Gear Request";
CM_ SG_ 444 APA_AMAPTqLimitVld_1BCh "AMAP function limit Tq valid
踏板误加速功能限制扭矩范围有效位";
CM_ SG_ 444 APA_CRC3_1BCh "Profile1A:E2E CRC (SAE J1850 CRC-8) for 8 Bytes
DataID:Reserved";
CM_ SG_ 444 APA_RollgCntr3_1BCh "Profile1A:E2E Rolling message counter(the maximum value of Alive counter is 14)";
CM_ SG_ 444 APA_Resd3_1BCh "Profile1A:E2E Reserved";
CM_ SG_ 444 APA_TarSpd_1BCh "蠕行车速,调试HPA";
CM_ SG_ 444 APA_ParkCtrlMod_1BCh "泊车功能控制模式
Parking control mode request";
CM_ SG_ 444 APA_GearCtrlEnable_1BCh "ADS Gear Control Enable";
CM_ SG_ 444 APA_EPBCtrlReqValid_1BCh "EPB功能请求有效";
CM_ SG_ 444 APA_ADCCAvl_1BCh "ADCC Function State
ADCC整体可用状态";
CM_ SG_ 444 APA_AMAPRequestVld_1BCh "域控ADCC 踏板误加速使能信
号有效值";
CM_ SG_ 444 APA_AMAPRequest_1BCh "域控ADCC 踏板误加速使能信
号";
CM_ SG_ 444 APA_DrvTarTqEnable_1BCh "ADS Drive traget torque  Request enable";

BA_DEF_ BU_ "ILused" ENUM "No","Yes";
BA_DEF_ BU_ "NmNode" ENUM "No","Yes";
BA_DEF_ BU_ "NodeLayerModules" STRING ;
BA_DEF_ "Baudrate" INT 0 1000000;
BA_DEF_ "BaudrateCANFD" INT 1000000 10000000;
BA_DEF_ "BusType" STRING ;
BA_DEF_ "DBName" STRING ;
BA_DEF_ "NmBaseAddress" HEX 1536 1663;
BA_DEF_ "NmMessageCount" INT 0 255;
BA_DEF_ "ProtocolType" STRING ;
BA_DEF_ SG_ "ASIL" ENUM "QM","A","B","C","D";
BA_DEF_ SG_ "E2EDataLength" INT 0 65535;
BA_DEF_ SG_ "GenSigInactiveValue" HEX 0 80000000;
BA_DEF_ SG_ "GenSigInvalidValue" HEX 0 281474976710655;
BA_DEF_ SG_ "GenSigStartValue" HEX 0 80000000;
BA_DEF_ SG_ "GenSigSendType" ENUM "Cyclic","OnWrite","OnWriteWithRepetition","OnChange","OnChangeWithRepetition","IfActive","IfActiveWithRepetition","NoSigSendType";
BA_DEF_ BO_ "CANFD_BRS" ENUM "0","1";
BA_DEF_ BO_ "DiagUudtResponse" ENUM "True","False";
BA_DEF_ BO_ "GenMsgCycleTime" INT 0 65535;
BA_DEF_ BO_ "GenMsgCycleTimeFast" INT 0 65535;
BA_DEF_ BO_ "GenMsgDelayTime" INT 0 65535;
BA_DEF_ BO_ "GenMsgILSupport" ENUM "No","Yes";
BA_DEF_ BO_ "GenMsgNrOfRepetition" INT 0 255;
BA_DEF_ BO_ "GenMsgSendType" ENUM "Cyclic","Event","IfActive","CE","CA","NoMsgSendType";
BA_DEF_ BO_ "MsgType" ENUM "IL","NM","DIAG","APPL";
BA_DEF_ BO_ "Msg_ASIL" ENUM "vector_leerstring","QM","A","B","C","D";
BA_DEF_ BO_ "NmAsrMessage" ENUM "No","Yes";
BA_DEF_ BO_ "NmMessage" ENUM "No","Yes";
BA_DEF_ BO_ "SCP_AuthInfoTxLength" INT 9 512;
BA_DEF_ BO_ "SCP_FreshnessValueLength" INT 0 512;
BA_DEF_ BO_ "SCP_FreshnessValueTxLength" INT 0 512;
BA_DEF_ BO_ "VFrameFormat" ENUM "StandardCAN","ExtendedCAN","reserved","J1939PG","reserved","reserved","reserved","reserved","reserved","reserved","reserved","reserved","reserved","reserved","StandardCAN_FD","ExtendedCAN_FD";
BA_DEF_DEF_ "ILused" "Yes";
BA_DEF_DEF_ "NmNode" "No";
BA_DEF_DEF_ "NodeLayerModules" "CANoeILNLSPA.dll";
BA_DEF_DEF_ "Baudrate" 500000;
BA_DEF_DEF_ "BaudrateCANFD" 2000000;
BA_DEF_DEF_ "BusType" "CAN";
BA_DEF_DEF_ "DBName" "CAN";
BA_DEF_DEF_ "NmBaseAddress" 1536;
BA_DEF_DEF_ "NmMessageCount" 128;
BA_DEF_DEF_ "ProtocolType" "CAN";
BA_DEF_DEF_ "ASIL" "QM";
BA_DEF_DEF_ "E2EDataLength" 64;
BA_DEF_DEF_ "GenSigInactiveValue" 0;
BA_DEF_DEF_ "GenSigInvalidValue" 0;
BA_DEF_DEF_ "GenSigStartValue" 0;
BA_DEF_DEF_ "GenSigSendType" "NoSigSendType";
BA_DEF_DEF_ "CANFD_BRS" "1";
BA_DEF_DEF_ "DiagUudtResponse" "True";
BA_DEF_DEF_ "GenMsgCycleTime" 0;
BA_DEF_DEF_ "GenMsgCycleTimeFast" 0;
BA_DEF_DEF_ "GenMsgDelayTime" 0;
BA_DEF_DEF_ "GenMsgILSupport" "Yes";
BA_DEF_DEF_ "GenMsgNrOfRepetition" 0;
BA_DEF_DEF_ "GenMsgSendType" "Cyclic";
BA_DEF_DEF_ "MsgType" "IL";
BA_DEF_DEF_ "Msg_ASIL" "vector_leerstring";
BA_DEF_DEF_ "NmAsrMessage" "No";
BA_DEF_DEF_ "NmMessage" "No";
BA_DEF_DEF_ "SCP_AuthInfoTxLength" 28;
BA_DEF_DEF_ "SCP_FreshnessValueLength" 48;
BA_DEF_DEF_ "SCP_FreshnessValueTxLength" 4;
BA_DEF_DEF_ "VFrameFormat" "J1939PG";
BA_ "BusType" "CAN FD";
BA_ "DBName" "FL_CH_CANFD";
BA_ "ILused" BU_ ACU 0;
BA_ "NodeLayerModules" BU_ ADCC "CANoeILNLVector.dll";
BA_ "ILused" BU_ ADCC 0;
BA_ "ILused" BU_ APA 0;
BA_ "ILused" BU_ EGS 0;
BA_ "ILused" BU_ EPS 0;
BA_ "NodeLayerModules" BU_ ESP "CANoeILNLVector.dll";
BA_ "ILused" BU_ ESP 0;
BA_ "ILused" BU_ FLZCU 0;
BA_ "ILused" BU_ ONEBOX 0;
BA_ "ILused" BU_ RXCU 0;
BA_ "GenMsgCycleTime" BO_ 33 10;
BA_ "VFrameFormat" BO_ 33 14;
BA_ "GenMsgCycleTime" BO_ 49 10;
BA_ "VFrameFormat" BO_ 49 14;
BA_ "GenMsgCycleTime" BO_ 56 10;
BA_ "VFrameFormat" BO_ 56 14;
BA_ "GenMsgCycleTime" BO_ 59 10;
BA_ "VFrameFormat" BO_ 59 14;
BA_ "GenMsgCycleTime" BO_ 75 10;
BA_ "VFrameFormat" BO_ 75 14;
BA_ "GenMsgCycleTime" BO_ 152 10;
BA_ "VFrameFormat" BO_ 152 14;
BA_ "GenMsgCycleTime" BO_ 168 10;
BA_ "VFrameFormat" BO_ 168 14;
BA_ "GenMsgCycleTime" BO_ 265 10;
BA_ "VFrameFormat" BO_ 265 14;
BA_ "GenMsgCycleTime" BO_ 306 10;
BA_ "VFrameFormat" BO_ 306 14;
BA_ "GenMsgCycleTime" BO_ 321 10;
BA_ "VFrameFormat" BO_ 321 14;
BA_ "GenMsgCycleTime" BO_ 325 10;
BA_ "VFrameFormat" BO_ 325 14;
BA_ "GenMsgCycleTime" BO_ 330 10;
BA_ "VFrameFormat" BO_ 330 14;
BA_ "GenMsgCycleTime" BO_ 335 10;
BA_ "VFrameFormat" BO_ 335 14;
BA_ "GenMsgCycleTime" BO_ 345 10;
BA_ "VFrameFormat" BO_ 345 14;
BA_ "GenMsgCycleTime" BO_ 359 10;
BA_ "VFrameFormat" BO_ 359 14;
BA_ "GenMsgCycleTime" BO_ 363 10;
BA_ "VFrameFormat" BO_ 363 14;
BA_ "GenMsgCycleTime" BO_ 364 10;
BA_ "VFrameFormat" BO_ 364 14;
BA_ "GenMsgCycleTime" BO_ 444 10;
BA_ "VFrameFormat" BO_ 444 14;
BA_ "GenSigSendType" SG_ 33 ACU_3_CRC1 0;
BA_ "GenSigSendType" SG_ 33 ACU_3_RollgCntr1 0;
BA_ "GenSigSendType" SG_ 33 ACU_3_Resd1 0;
BA_ "GenSigInvalidValue" SG_ 33 ACU_3_LongitudinalAcceleration 65535;
BA_ "GenSigStartValue" SG_ 33 ACU_3_LongitudinalAcceleration 2000;
BA_ "ASIL" SG_ 33 ACU_3_LongitudinalAcceleration 2;
BA_ "GenSigSendType" SG_ 33 ACU_3_LongitudinalAcceleration 0;
BA_ "ASIL" SG_ 33 ACU_3_SCMRequest 2;
BA_ "GenSigSendType" SG_ 33 ACU_3_SCMRequest 0;
BA_ "GenSigStartValue" SG_ 33 ACU_3_LongitudinalAccelerationVD 3;
BA_ "ASIL" SG_ 33 ACU_3_LongitudinalAccelerationVD 2;
BA_ "GenSigSendType" SG_ 33 ACU_3_LongitudinalAccelerationVD 0;
BA_ "ASIL" SG_ 33 ACU_3_CrashOutputSts 2;
BA_ "GenSigSendType" SG_ 33 ACU_3_CrashOutputSts 0;
BA_ "GenSigSendType" SG_ 49 ACU_2_CRC1 0;
BA_ "GenSigSendType" SG_ 49 ACU_2_RollgCntr1 0;
BA_ "GenSigSendType" SG_ 49 ACU_2_Resd1 0;
BA_ "GenSigInvalidValue" SG_ 49 ACU_2_LateralAcceleration 65535;
BA_ "GenSigStartValue" SG_ 49 ACU_2_LateralAcceleration 2000;
BA_ "ASIL" SG_ 49 ACU_2_LateralAcceleration 2;
BA_ "GenSigSendType" SG_ 49 ACU_2_LateralAcceleration 0;
BA_ "GenSigInvalidValue" SG_ 49 ACU_2_YawRate 65535;
BA_ "GenSigStartValue" SG_ 49 ACU_2_YawRate 18000;
BA_ "ASIL" SG_ 49 ACU_2_YawRate 2;
BA_ "GenSigSendType" SG_ 49 ACU_2_YawRate 0;
BA_ "GenSigStartValue" SG_ 49 ACU_2_YASCalibrationSts 1;
BA_ "ASIL" SG_ 49 ACU_2_YASCalibrationSts 2;
BA_ "GenSigSendType" SG_ 49 ACU_2_YASCalibrationSts 0;
BA_ "GenSigStartValue" SG_ 49 ACU_2_YawrateSigValidData 3;
BA_ "ASIL" SG_ 49 ACU_2_YawrateSigValidData 2;
BA_ "GenSigSendType" SG_ 49 ACU_2_YawrateSigValidData 0;
BA_ "GenSigStartValue" SG_ 49 ACU_2_LateralAccelerationSigVD 3;
BA_ "ASIL" SG_ 49 ACU_2_LateralAccelerationSigVD 2;
BA_ "GenSigSendType" SG_ 49 ACU_2_LateralAccelerationSigVD 0;
BA_ "GenSigSendType" SG_ 56 VCU_10_CRC 0;
BA_ "GenSigSendType" SG_ 56 VCU_10_RollgCntr 0;
BA_ "GenSigSendType" SG_ 56 VCU_10_Resd 0;
BA_ "GenSigSendType" SG_ 56 VCU_10_ShiftInProgress 0;
BA_ "GenSigSendType" SG_ 56 VCU_10_ShiftInProgressValidData 0;
BA_ "ASIL" SG_ 56 VCU_10_TargetGear 2;
BA_ "GenSigSendType" SG_ 56 VCU_10_TargetGear 0;
BA_ "ASIL" SG_ 56 VCU_10_ActualGear 2;
BA_ "GenSigSendType" SG_ 56 VCU_10_ActualGear 0;
BA_ "ASIL" SG_ 56 VCU_10_TargetGearValidData 2;
BA_ "GenSigSendType" SG_ 56 VCU_10_TargetGearValidData 0;
BA_ "ASIL" SG_ 56 VCU_10_ActualGearValidData 2;
BA_ "GenSigSendType" SG_ 56 VCU_10_ActualGearValidData 0;
BA_ "GenSigSendType" SG_ 56 VCU_10_BrakePedalStsValidData 0;
BA_ "ASIL" SG_ 56 VCU_10_BrakePedalSts 2;
BA_ "GenSigSendType" SG_ 56 VCU_10_BrakePedalSts 0;
BA_ "ASIL" SG_ 56 VCU_10_TowingMode 2;
BA_ "GenSigSendType" SG_ 56 VCU_10_TowingMode 0;
BA_ "ASIL" SG_ 56 HCU_TCUR_GearShiftProgFlag 2;
BA_ "GenSigSendType" SG_ 56 HCU_TCUR_GearShiftProgFlag 0;
BA_ "GenSigSendType" SG_ 56 VCU_10_CRC2 0;
BA_ "GenSigSendType" SG_ 56 VCU_10_RollgCntr2 0;
BA_ "GenSigSendType" SG_ 56 VCU_10_Resd2 0;
BA_ "GenSigSendType" SG_ 59 VCU_11_CRC1 0;
BA_ "GenSigSendType" SG_ 59 VCU_11_RollgCntr1 0;
BA_ "GenSigSendType" SG_ 59 VCU_11_Resd1 0;
BA_ "GenSigStartValue" SG_ 59 VCU_11_IndicatedDriverReqWhlTqFA 32768;
BA_ "ASIL" SG_ 59 VCU_11_IndicatedDriverReqWhlTqFA 3;
BA_ "GenSigSendType" SG_ 59 VCU_11_IndicatedDriverReqWhlTqFA 0;
BA_ "GenSigStartValue" SG_ 59 VCU_11_ActWheelTorqueFA 32768;
BA_ "ASIL" SG_ 59 VCU_11_ActWheelTorqueFA 2;
BA_ "GenSigSendType" SG_ 59 VCU_11_ActWheelTorqueFA 0;
BA_ "GenSigInvalidValue" SG_ 59 VCU_11_ActWheelSpdFA 65535;
BA_ "GenSigStartValue" SG_ 59 VCU_11_ActWheelSpdFA 32767;
BA_ "GenSigSendType" SG_ 59 VCU_11_ActWheelSpdFA 0;
BA_ "GenSigSendType" SG_ 59 VCU_11_CRC2 0;
BA_ "GenSigSendType" SG_ 59 VCU_11_RollgCntr2 0;
BA_ "GenSigSendType" SG_ 59 VCU_11_Resd2 0;
BA_ "GenSigStartValue" SG_ 59 VCU_11_IndcdDriverReqWhlTqStsFA 1;
BA_ "ASIL" SG_ 59 VCU_11_IndcdDriverReqWhlTqStsFA 2;
BA_ "GenSigSendType" SG_ 59 VCU_11_IndcdDriverReqWhlTqStsFA 0;
BA_ "GenSigStartValue" SG_ 59 VCU_11_ActWheelTorqueStsFA 1;
BA_ "ASIL" SG_ 59 VCU_11_ActWheelTorqueStsFA 3;
BA_ "GenSigSendType" SG_ 59 VCU_11_ActWheelTorqueStsFA 0;
BA_ "GenSigStartValue" SG_ 59 VCU_11_ActWheelSpdStsFA 1;
BA_ "GenSigSendType" SG_ 59 VCU_11_ActWheelSpdStsFA 0;
BA_ "GenSigSendType" SG_ 59 VCU_11_MotorReadyFMCU 0;
BA_ "GenSigStartValue" SG_ 59 VCU_11_IndicatedDriverReqWhlTqRA 32768;
BA_ "ASIL" SG_ 59 VCU_11_IndicatedDriverReqWhlTqRA 3;
BA_ "GenSigSendType" SG_ 59 VCU_11_IndicatedDriverReqWhlTqRA 0;
BA_ "GenSigStartValue" SG_ 59 VCU_11_ActWheelTorqueRA 32768;
BA_ "ASIL" SG_ 59 VCU_11_ActWheelTorqueRA 2;
BA_ "GenSigSendType" SG_ 59 VCU_11_ActWheelTorqueRA 0;
BA_ "GenSigSendType" SG_ 59 VCU_11_CRC3 0;
BA_ "GenSigSendType" SG_ 59 VCU_11_RollgCntr3 0;
BA_ "GenSigSendType" SG_ 59 VCU_11_Resd3 0;
BA_ "GenSigInvalidValue" SG_ 59 VCU_11_ActWheelSpdRA 65535;
BA_ "GenSigStartValue" SG_ 59 VCU_11_ActWheelSpdRA 32767;
BA_ "GenSigSendType" SG_ 59 VCU_11_ActWheelSpdRA 0;
BA_ "GenSigStartValue" SG_ 59 VCU_11_IndcdDriverReqWhlTqStsRA 1;
BA_ "ASIL" SG_ 59 VCU_11_IndcdDriverReqWhlTqStsRA 2;
BA_ "GenSigSendType" SG_ 59 VCU_11_IndcdDriverReqWhlTqStsRA 0;
BA_ "GenSigStartValue" SG_ 59 VCU_11_ActWheelTorqueStsRA 1;
BA_ "GenSigSendType" SG_ 59 VCU_11_ActWheelTorqueStsRA 0;
BA_ "GenSigSendType" SG_ 59 VCU_11_MotorReadyRMCU 0;
BA_ "GenSigStartValue" SG_ 59 VCU_11_ActWheelSpdStsRA 1;
BA_ "GenSigSendType" SG_ 59 VCU_11_ActWheelSpdStsRA 0;
BA_ "GenSigStartValue" SG_ 59 VCU_11_MbRegenMaxWheel 32768;
BA_ "ASIL" SG_ 59 VCU_11_MbRegenMaxWheel 3;
BA_ "GenSigSendType" SG_ 59 VCU_11_MbRegenMaxWheel 0;
BA_ "GenSigSendType" SG_ 59 VCU_11_CRC4 0;
BA_ "GenSigSendType" SG_ 59 VCU_11_RollgCntr4 0;
BA_ "GenSigSendType" SG_ 59 VCU_11_Resd4 0;
BA_ "GenSigStartValue" SG_ 59 VCU_11_MbRegenWheel 32768;
BA_ "ASIL" SG_ 59 VCU_11_MbRegenWheel 3;
BA_ "GenSigSendType" SG_ 59 VCU_11_MbRegenWheel 0;
BA_ "GenSigSendType" SG_ 59 VCU_11_MbRegenMaxWheelQualifier 0;
BA_ "GenSigSendType" SG_ 59 VCU_11_MbRegenWheelQualifier 0;
BA_ "ASIL" SG_ 59 VCU_11_EPBReq 3;
BA_ "GenSigSendType" SG_ 59 VCU_11_EPBReq 0;
BA_ "ASIL" SG_ 59 VCU_11_GasPedalPosInvalidData 2;
BA_ "GenSigSendType" SG_ 59 VCU_11_GasPedalPosInvalidData 0;
BA_ "ASIL" SG_ 59 VCU_11_AcceleratorPosRawIVD 2;
BA_ "GenSigSendType" SG_ 59 VCU_11_AcceleratorPosRawIVD 0;
BA_ "GenSigInvalidValue" SG_ 59 VCU_11_GasPedalPosition 1023;
BA_ "ASIL" SG_ 59 VCU_11_GasPedalPosition 2;
BA_ "GenSigSendType" SG_ 59 VCU_11_GasPedalPosition 0;
BA_ "GenSigInvalidValue" SG_ 59 VCU_11_AcceleratorPosRaw 1023;
BA_ "ASIL" SG_ 59 VCU_11_AcceleratorPosRaw 2;
BA_ "GenSigSendType" SG_ 59 VCU_11_AcceleratorPosRaw 0;
BA_ "GenSigSendType" SG_ 59 VCU_11_EPBReqValid 0;
BA_ "GenSigSendType" SG_ 59 VCU_11_CRC5 0;
BA_ "GenSigSendType" SG_ 59 VCU_11_RollgCntr5 0;
BA_ "GenSigSendType" SG_ 59 VCU_11_Resd5 0;
BA_ "GenSigStartValue" SG_ 59 VCU_11_CoastRegenTargetWheelFA 32768;
BA_ "GenSigSendType" SG_ 59 VCU_11_CoastRegenTargetWheelFA 0;
BA_ "GenSigSendType" SG_ 59 VCU_11_CoastRegenTargetWheelFAQ 0;
BA_ "GenSigStartValue" SG_ 59 VCU_11_CoastRegenTargetWheelRA 32768;
BA_ "GenSigSendType" SG_ 59 VCU_11_CoastRegenTargetWheelRA 0;
BA_ "GenSigSendType" SG_ 59 VCU_11_CoastRegenTargetWheelRAQ 0;
BA_ "GenSigSendType" SG_ 59 VCU_11_CRC6 0;
BA_ "GenSigSendType" SG_ 59 VCU_11_RollgCntr6 0;
BA_ "GenSigSendType" SG_ 59 VCU_11_Resd6 0;
BA_ "GenSigStartValue" SG_ 59 VCU_11_MaxWheelTorqueFA 32768;
BA_ "GenSigSendType" SG_ 59 VCU_11_MaxWheelTorqueFA 0;
BA_ "GenSigStartValue" SG_ 59 VCU_11_MaxWheelTorqueRA 32768;
BA_ "GenSigSendType" SG_ 59 VCU_11_MaxWheelTorqueRA 0;
BA_ "GenSigInvalidValue" SG_ 59 HCU_11_iTASRearTorque_Max 65535;
BA_ "GenSigSendType" SG_ 59 HCU_11_iTASRearTorque_Max 0;
BA_ "GenSigSendType" SG_ 59 VCU_11_CRC7 0;
BA_ "GenSigSendType" SG_ 59 VCU_11_RollgCntr7 0;
BA_ "GenSigSendType" SG_ 59 VCU_11_Resd7 0;
BA_ "GenSigSendType" SG_ 59 VCU_11_OPDHoldRequest 0;
BA_ "GenSigSendType" SG_ 59 VCU_11_OPDHydBrkCompenRqSts 0;
BA_ "GenSigSendType" SG_ 59 VCU_11_OnePedalstatus 0;
BA_ "GenSigStartValue" SG_ 59 VCU_11_OPDHydBrkCompenRqTq 65535;
BA_ "GenSigSendType" SG_ 59 VCU_11_OPDHydBrkCompenRqTq 0;
BA_ "GenSigSendType" SG_ 59 HCU_11_RearWheelDir 0;
BA_ "GenSigSendType" SG_ 59 VCU_11_DrivingModReq 0;
BA_ "GenSigInvalidValue" SG_ 59 HCU_11_iTASFrontTorque_Max 65535;
BA_ "GenSigSendType" SG_ 59 HCU_11_iTASFrontTorque_Max 0;
BA_ "GenSigSendType" SG_ 59 VCU_11_CRC8 0;
BA_ "GenSigSendType" SG_ 59 VCU_11_RollgCntr8 0;
BA_ "GenSigSendType" SG_ 59 VCU_11_Resd8 0;
BA_ "GenSigSendType" SG_ 75 VCU_12_CRC1 0;
BA_ "GenSigSendType" SG_ 75 VCU_12_RollgCntr1 0;
BA_ "ASIL" SG_ 75 VCU_12_Resd1 2;
BA_ "GenSigSendType" SG_ 75 VCU_12_Resd1 0;
BA_ "GenSigStartValue" SG_ 75 VCU_12_DriverTorqueDesired 32768;
BA_ "ASIL" SG_ 75 VCU_12_DriverTorqueDesired 2;
BA_ "GenSigSendType" SG_ 75 VCU_12_DriverTorqueDesired 0;
BA_ "GenSigStartValue" SG_ 75 VCU_12_VehWhlActTq 32768;
BA_ "ASIL" SG_ 75 VCU_12_VehWhlActTq 2;
BA_ "GenSigSendType" SG_ 75 VCU_12_VehWhlActTq 0;
BA_ "GenSigStartValue" SG_ 75 VCU_12_VehWhlActTqVld 1;
BA_ "ASIL" SG_ 75 VCU_12_VehWhlActTqVld 2;
BA_ "GenSigSendType" SG_ 75 VCU_12_VehWhlActTqVld 0;
BA_ "ASIL" SG_ 75 VCU_12_DrvrGearIntervention 2;
BA_ "GenSigSendType" SG_ 75 VCU_12_DrvrGearIntervention 0;
BA_ "ASIL" SG_ 75 VCU_12_PtTqActvSts 2;
BA_ "GenSigSendType" SG_ 75 VCU_12_PtTqActvSts 0;
BA_ "ASIL" SG_ 75 VCU_12_PtTqAvl 2;
BA_ "GenSigSendType" SG_ 75 VCU_12_PtTqAvl 0;
BA_ "ASIL" SG_ 75 VCU_12_DrvrAccrPedlOvrd 2;
BA_ "GenSigSendType" SG_ 75 VCU_12_DrvrAccrPedlOvrd 0;
BA_ "ASIL" SG_ 75 VCU_12_DrvrAccrPedlOvrdInVD 2;
BA_ "GenSigSendType" SG_ 75 VCU_12_DrvrAccrPedlOvrdInVD 0;
BA_ "GenSigSendType" SG_ 75 VCU_12_CRC2 0;
BA_ "GenSigSendType" SG_ 75 VCU_12_RollgCntr2 0;
BA_ "GenSigSendType" SG_ 75 VCU_12_Resd2 0;
BA_ "GenSigStartValue" SG_ 75 VCU_12_PtTqMax 32768;
BA_ "ASIL" SG_ 75 VCU_12_PtTqMax 2;
BA_ "GenSigSendType" SG_ 75 VCU_12_PtTqMax 0;
BA_ "GenSigStartValue" SG_ 75 HCU_12_PtTqMinVld 1;
BA_ "ASIL" SG_ 75 HCU_12_PtTqMinVld 2;
BA_ "GenSigSendType" SG_ 75 HCU_12_PtTqMinVld 0;
BA_ "GenSigSendType" SG_ 75 TargetGearTransInp 0;
BA_ "ASIL" SG_ 75 VCU_12_GasPedalInhabition 2;
BA_ "GenSigSendType" SG_ 75 VCU_12_GasPedalInhabition 0;
BA_ "GenSigStartValue" SG_ 75 VCU_12_PtTqMaxVld 1;
BA_ "ASIL" SG_ 75 VCU_12_PtTqMaxVld 2;
BA_ "GenSigSendType" SG_ 75 VCU_12_PtTqMaxVld 0;
BA_ "GenSigStartValue" SG_ 75 HCU_12_PtTqMin 32768;
BA_ "ASIL" SG_ 75 HCU_12_PtTqMin 2;
BA_ "GenSigSendType" SG_ 75 HCU_12_PtTqMin 0;
BA_ "GenSigSendType" SG_ 75 HCU_26_TargetGearEM2 0;
BA_ "GenSigSendType" SG_ 75 VCU_12_CRC3 0;
BA_ "GenSigSendType" SG_ 75 VCU_12_RollgCntr3 0;
BA_ "GenSigSendType" SG_ 75 VCU_12_Resd3 0;
BA_ "ASIL" SG_ 75 VCU_12_VehWhlActTqADS 2;
BA_ "GenSigSendType" SG_ 75 VCU_12_VehWhlActTqADS 0;
BA_ "GenSigStartValue" SG_ 75 VCU_12_VehWhlActTqADSVld 1;
BA_ "ASIL" SG_ 75 VCU_12_VehWhlActTqADSVld 2;
BA_ "GenSigSendType" SG_ 75 VCU_12_VehWhlActTqADSVld 0;
BA_ "GenSigSendType" SG_ 152 ONEBOX_1_CRC1 0;
BA_ "GenSigSendType" SG_ 152 ONEBOX_1_RollgCntr1 0;
BA_ "GenSigSendType" SG_ 152 ONEBOX_1_Resd1 0;
BA_ "GenSigInvalidValue" SG_ 152 ABS_ESP_1_VehicleSpeedVSOSig 8191;
BA_ "ASIL" SG_ 152 ABS_ESP_1_VehicleSpeedVSOSig 3;
BA_ "GenSigSendType" SG_ 152 ABS_ESP_1_VehicleSpeedVSOSig 0;
BA_ "ASIL" SG_ 152 ABS_ESP_1_ABSFailSts 4;
BA_ "GenSigSendType" SG_ 152 ABS_ESP_1_ABSFailSts 0;
BA_ "ASIL" SG_ 152 ABS_ESP_1_EBDFailSts 2;
BA_ "GenSigSendType" SG_ 152 ABS_ESP_1_EBDFailSts 0;
BA_ "GenSigStartValue" SG_ 152 ESP1_VehicleSpeedVSOSigValidData 1;
BA_ "ASIL" SG_ 152 ESP1_VehicleSpeedVSOSigValidData 4;
BA_ "GenSigSendType" SG_ 152 ESP1_VehicleSpeedVSOSigValidData 0;
BA_ "GenSigInvalidValue" SG_ 152 ONEBOX_1_IPB_SimulatorPressure 1023;
BA_ "ASIL" SG_ 152 ONEBOX_1_IPB_SimulatorPressure 2;
BA_ "GenSigSendType" SG_ 152 ONEBOX_1_IPB_SimulatorPressure 0;
BA_ "GenSigStartValue" SG_ 152 IPB_SimulatorPressureSts 1;
BA_ "ASIL" SG_ 152 IPB_SimulatorPressureSts 2;
BA_ "GenSigSendType" SG_ 152 IPB_SimulatorPressureSts 0;
BA_ "ASIL" SG_ 152 ABS_ESP_1_ABSActive 4;
BA_ "GenSigSendType" SG_ 152 ABS_ESP_1_ABSActive 0;
BA_ "ASIL" SG_ 152 ABS_ESP_1_VDCFailSts 4;
BA_ "GenSigSendType" SG_ 152 ABS_ESP_1_VDCFailSts 0;
BA_ "ASIL" SG_ 152 ABS_ESP_1_VDCActive 4;
BA_ "GenSigSendType" SG_ 152 ABS_ESP_1_VDCActive 0;
BA_ "ASIL" SG_ 152 ABS_ESP_1_TCSFailSts 4;
BA_ "GenSigSendType" SG_ 152 ABS_ESP_1_TCSFailSts 0;
BA_ "ASIL" SG_ 152 ABS_ESP_1_TCSActive 4;
BA_ "GenSigSendType" SG_ 152 ABS_ESP_1_TCSActive 0;
BA_ "GenSigSendType" SG_ 152 BrakeSystemType 0;
BA_ "GenSigSendType" SG_ 152 ABS_ESP_1_HHCFailSts 0;
BA_ "GenSigSendType" SG_ 152 ONEBOX_1_HHCActive 0;
BA_ "GenSigSendType" SG_ 152 ABS_ESP_1_HDCCtrlSts 0;
BA_ "GenSigSendType" SG_ 152 ABS_ESP_1_HDCFailSts 0;
BA_ "GenSigSendType" SG_ 152 ONEBOX_1_HLRequest 0;
BA_ "ASIL" SG_ 152 ABS_ESP_1_ESPSwitchStatus 2;
BA_ "GenSigSendType" SG_ 152 ABS_ESP_1_ESPSwitchStatus 0;
BA_ "ASIL" SG_ 152 ONEBOX_1_BLRequestController 2;
BA_ "GenSigSendType" SG_ 152 ONEBOX_1_BLRequestController 0;
BA_ "ASIL" SG_ 152 SwitchOffCruiseControl 2;
BA_ "GenSigSendType" SG_ 152 SwitchOffCruiseControl 0;
BA_ "GenSigSendType" SG_ 152 ONEBOX_1_CRC2 0;
BA_ "GenSigSendType" SG_ 152 ONEBOX_1_RollgCntr2 0;
BA_ "GenSigSendType" SG_ 152 ONEBOX_1_Resd2 0;
BA_ "GenSigStartValue" SG_ 152 IPB_1_MbRegenTargetWheel 32768;
BA_ "ASIL" SG_ 152 IPB_1_MbRegenTargetWheel 2;
BA_ "GenSigSendType" SG_ 152 IPB_1_MbRegenTargetWheel 0;
BA_ "ASIL" SG_ 152 IPB_1_MbRegenTargetWheelQ 2;
BA_ "GenSigSendType" SG_ 152 IPB_1_MbRegenTargetWheelQ 0;
BA_ "ASIL" SG_ 152 ONEBOX_1_AEBdecActive 2;
BA_ "GenSigSendType" SG_ 152 ONEBOX_1_AEBdecActive 0;
BA_ "ASIL" SG_ 152 ONEBOX_1_AEBdecAvailable 2;
BA_ "GenSigSendType" SG_ 152 ONEBOX_1_AEBdecAvailable 0;
BA_ "ASIL" SG_ 152 ONEBOX_1_CDPActive 2;
BA_ "GenSigSendType" SG_ 152 ONEBOX_1_CDPActive 0;
BA_ "GenSigSendType" SG_ 152 Reserve_EPBStatus 0;
BA_ "ASIL" SG_ 152 ONEBOX_1_CDPFailSts 2;
BA_ "GenSigSendType" SG_ 152 ONEBOX_1_CDPFailSts 0;
BA_ "GenSigSendType" SG_ 152 ONEBOX_1_CRC3 0;
BA_ "GenSigSendType" SG_ 152 ONEBOX_1_RollgCntr3 0;
BA_ "GenSigSendType" SG_ 152 ONEBOX_1_Resd3 0;
BA_ "GenSigSendType" SG_ 168 ONEBOX_2_CRC1 0;
BA_ "GenSigSendType" SG_ 168 ONEBOX_2_RollgCntr1 0;
BA_ "GenSigSendType" SG_ 168 ONEBOX_2_Resd1 0;
BA_ "GenSigInvalidValue" SG_ 168 LHFWheelSpeed_0A8h 8191;
BA_ "ASIL" SG_ 168 LHFWheelSpeed_0A8h 2;
BA_ "GenSigSendType" SG_ 168 LHFWheelSpeed_0A8h 0;
BA_ "GenSigStartValue" SG_ 168 LHFWheelSpeedValidData_0A8h 1;
BA_ "ASIL" SG_ 168 LHFWheelSpeedValidData_0A8h 2;
BA_ "GenSigSendType" SG_ 168 LHFWheelSpeedValidData_0A8h 0;
BA_ "GenSigInvalidValue" SG_ 168 RHFWheelSpeed_0A8h 8191;
BA_ "ASIL" SG_ 168 RHFWheelSpeed_0A8h 2;
BA_ "GenSigSendType" SG_ 168 RHFWheelSpeed_0A8h 0;
BA_ "GenSigStartValue" SG_ 168 RHFWheelSpeedValidData_0A8h 1;
BA_ "ASIL" SG_ 168 RHFWheelSpeedValidData_0A8h 2;
BA_ "GenSigSendType" SG_ 168 RHFWheelSpeedValidData_0A8h 0;
BA_ "GenSigInvalidValue" SG_ 168 LHRWheelSpeed_0A8h 8191;
BA_ "ASIL" SG_ 168 LHRWheelSpeed_0A8h 2;
BA_ "GenSigSendType" SG_ 168 LHRWheelSpeed_0A8h 0;
BA_ "GenSigStartValue" SG_ 168 LHRWheelSpeedValidData_0A8h 1;
BA_ "ASIL" SG_ 168 LHRWheelSpeedValidData_0A8h 2;
BA_ "GenSigSendType" SG_ 168 LHRWheelSpeedValidData_0A8h 0;
BA_ "GenSigSendType" SG_ 168 ONEBOX_2_CRC2 0;
BA_ "GenSigSendType" SG_ 168 ONEBOX_2_RollgCntr2 0;
BA_ "GenSigSendType" SG_ 168 ONEBOX_2_Resd2 0;
BA_ "GenSigInvalidValue" SG_ 168 RHRWheelSpeed_0A8h 8191;
BA_ "ASIL" SG_ 168 RHRWheelSpeed_0A8h 2;
BA_ "GenSigSendType" SG_ 168 RHRWheelSpeed_0A8h 0;
BA_ "GenSigStartValue" SG_ 168 RHRWheelSpeedValidData_0A8h 1;
BA_ "ASIL" SG_ 168 RHRWheelSpeedValidData_0A8h 2;
BA_ "GenSigSendType" SG_ 168 RHRWheelSpeedValidData_0A8h 0;
BA_ "GenSigInvalidValue" SG_ 168 LHFWheelSpeedRPM 65535;
BA_ "ASIL" SG_ 168 LHFWheelSpeedRPM 4;
BA_ "GenSigSendType" SG_ 168 LHFWheelSpeedRPM 0;
BA_ "GenSigInvalidValue" SG_ 168 RHFWheelSpeedRPM 65535;
BA_ "ASIL" SG_ 168 RHFWheelSpeedRPM 4;
BA_ "GenSigSendType" SG_ 168 RHFWheelSpeedRPM 0;
BA_ "GenSigSendType" SG_ 168 ONEBOX_2_CRC3 0;
BA_ "GenSigSendType" SG_ 168 ONEBOX_2_RollgCntr3 0;
BA_ "GenSigSendType" SG_ 168 ONEBOX_2_Resd3 0;
BA_ "GenSigInvalidValue" SG_ 168 LHRWheelSpeedRPM_0A8h 65535;
BA_ "ASIL" SG_ 168 LHRWheelSpeedRPM_0A8h 2;
BA_ "GenSigSendType" SG_ 168 LHRWheelSpeedRPM_0A8h 0;
BA_ "GenSigInvalidValue" SG_ 168 RHRWheelSpeedRPM_0A8h 65535;
BA_ "ASIL" SG_ 168 RHRWheelSpeedRPM_0A8h 2;
BA_ "GenSigSendType" SG_ 168 RHRWheelSpeedRPM_0A8h 0;
BA_ "GenSigStartValue" SG_ 168 RHFWheelSpeedRPMValidData 1;
BA_ "ASIL" SG_ 168 RHFWheelSpeedRPMValidData 2;
BA_ "GenSigSendType" SG_ 168 RHFWheelSpeedRPMValidData 0;
BA_ "GenSigStartValue" SG_ 168 LHFWheelSpeedRPMValidData 1;
BA_ "ASIL" SG_ 168 LHFWheelSpeedRPMValidData 2;
BA_ "GenSigSendType" SG_ 168 LHFWheelSpeedRPMValidData 0;
BA_ "GenSigInvalidValue" SG_ 168 RHFWheelDriveDirection_0A8h 4;
BA_ "ASIL" SG_ 168 RHFWheelDriveDirection_0A8h 2;
BA_ "GenSigSendType" SG_ 168 RHFWheelDriveDirection_0A8h 0;
BA_ "GenSigInvalidValue" SG_ 168 LHFWheelDriveDirection_0A8h 4;
BA_ "ASIL" SG_ 168 LHFWheelDriveDirection_0A8h 2;
BA_ "GenSigSendType" SG_ 168 LHFWheelDriveDirection_0A8h 0;
BA_ "GenSigStartValue" SG_ 168 RHRWheelSpeedRPMValidData 1;
BA_ "ASIL" SG_ 168 RHRWheelSpeedRPMValidData 2;
BA_ "GenSigSendType" SG_ 168 RHRWheelSpeedRPMValidData 0;
BA_ "GenSigStartValue" SG_ 168 LHRWheelSpeedRPMValidData 1;
BA_ "ASIL" SG_ 168 LHRWheelSpeedRPMValidData 2;
BA_ "GenSigSendType" SG_ 168 LHRWheelSpeedRPMValidData 0;
BA_ "GenSigInvalidValue" SG_ 168 RHRWheelDriveDirection_0A8h 4;
BA_ "ASIL" SG_ 168 RHRWheelDriveDirection_0A8h 2;
BA_ "GenSigSendType" SG_ 168 RHRWheelDriveDirection_0A8h 0;
BA_ "GenSigInvalidValue" SG_ 168 LHRWheelDriveDirection_0A8h 4;
BA_ "ASIL" SG_ 168 LHRWheelDriveDirection_0A8h 2;
BA_ "GenSigSendType" SG_ 168 LHRWheelDriveDirection_0A8h 0;
BA_ "GenSigSendType" SG_ 265 ONEBOX_CRC1_109h 0;
BA_ "GenSigSendType" SG_ 265 ONEBOX_RollgCntr1_109h 0;
BA_ "GenSigSendType" SG_ 265 ONEBOX_Resd1_109h 0;
BA_ "ASIL" SG_ 265 ONEBOX_AebBrkTqAvl_109h 3;
BA_ "GenSigSendType" SG_ 265 ONEBOX_AebBrkTqAvl_109h 0;
BA_ "ASIL" SG_ 265 ONEBOX_AebBrkTqActv_109h 3;
BA_ "GenSigSendType" SG_ 265 ONEBOX_AebBrkTqActv_109h 0;
BA_ "ASIL" SG_ 265 ONEBOX_DrvrBrkOvrdVld_109h 4;
BA_ "GenSigSendType" SG_ 265 ONEBOX_DrvrBrkOvrdVld_109h 0;
BA_ "ASIL" SG_ 265 ONEBOX_DrvrBrkOvrd_109h 4;
BA_ "GenSigSendType" SG_ 265 ONEBOX_DrvrBrkOvrd_109h 0;
BA_ "GenSigSendType" SG_ 306 SAM_1_CRC 0;
BA_ "GenSigSendType" SG_ 306 SAM_1_RollgCntr 0;
BA_ "GenSigSendType" SG_ 306 SAM_1_Resd 0;
BA_ "GenSigInvalidValue" SG_ 306 SAM_1_SteeringAngle 65535;
BA_ "GenSigStartValue" SG_ 306 SAM_1_SteeringAngle 65535;
BA_ "GenSigSendType" SG_ 306 SAM_1_SteeringAngle 0;
BA_ "GenSigInvalidValue" SG_ 306 SAM_1_SteeringAngleSpeed 255;
BA_ "GenSigStartValue" SG_ 306 SAM_1_SteeringAngleSpeed 255;
BA_ "GenSigSendType" SG_ 306 SAM_1_SteeringAngleSpeed 0;
BA_ "GenSigStartValue" SG_ 306 SAM_1_SteeringAngleSpeedVD 1;
BA_ "GenSigSendType" SG_ 306 SAM_1_SteeringAngleSpeedVD 0;
BA_ "GenSigStartValue" SG_ 306 SAM_1_SteeringAngleVD 1;
BA_ "GenSigSendType" SG_ 306 SAM_1_SteeringAngleVD 0;
BA_ "GenSigSendType" SG_ 306 SAM_1_SASCalibrated 0;
BA_ "GenSigSendType" SG_ 306 SAM_1_SASInit 0;
BA_ "GenSigSendType" SG_ 306 SAM_1_CANWarning 0;
BA_ "GenSigSendType" SG_ 306 SAM_1_InternalFailure 0;
BA_ "GenSigSendType" SG_ 306 SAM_1_BatteryWarning 0;
BA_ "GenSigSendType" SG_ 306 SAM_1_AngleFailure 0;
BA_ "GenSigSendType" SG_ 321 CSA_1_CRC 0;
BA_ "GenSigSendType" SG_ 321 CSA_1_RollgCntr 0;
BA_ "GenSigSendType" SG_ 321 CSA_1_Resd 0;
BA_ "GenSigStartValue" SG_ 321 GearShiftPos 15;
BA_ "ASIL" SG_ 321 GearShiftPos 2;
BA_ "GenSigSendType" SG_ 321 GearShiftPos 0;
BA_ "ASIL" SG_ 321 GearShiftPosInverse 2;
BA_ "GenSigSendType" SG_ 321 GearShiftPosInverse 0;
BA_ "ASIL" SG_ 321 STAT_ParkButton 2;
BA_ "GenSigSendType" SG_ 321 STAT_ParkButton 0;
BA_ "ASIL" SG_ 321 STAT_ShifterLeverFault 2;
BA_ "GenSigSendType" SG_ 321 STAT_ShifterLeverFault 0;
BA_ "GenSigSendType" SG_ 321 DriveModeActive 0;
BA_ "GenSigSendType" SG_ 321 DriveModeReq 0;
BA_ "GenSigSendType" SG_ 325 FCM_2_CRC1 0;
BA_ "GenSigSendType" SG_ 325 FCM_2_RollgCntr1 0;
BA_ "GenSigSendType" SG_ 325 FCM_2_Resd1 0;
BA_ "GenSigStartValue" SG_ 325 FCM_2_AebTarDec 2000;
BA_ "ASIL" SG_ 325 FCM_2_AebTarDec 2;
BA_ "GenSigSendType" SG_ 325 FCM_2_AebTarDec 0;
BA_ "ASIL" SG_ 325 FCM_2_AebReqTyp 2;
BA_ "GenSigSendType" SG_ 325 FCM_2_AebReqTyp 0;
BA_ "ASIL" SG_ 325 FCM_2_AebTarDecVld 2;
BA_ "GenSigSendType" SG_ 325 FCM_2_AebTarDecVld 0;
BA_ "ASIL" SG_ 325 FCM_2_AwbReq 2;
BA_ "GenSigSendType" SG_ 325 FCM_2_AwbReq 0;
BA_ "ASIL" SG_ 325 FCM_2_AwbLvl 2;
BA_ "GenSigSendType" SG_ 325 FCM_2_AwbLvl 0;
BA_ "GenSigSendType" SG_ 325 FCM_2_BrkPreFillReq 0;
BA_ "ASIL" SG_ 325 FCM_2_AbaReq 2;
BA_ "GenSigSendType" SG_ 325 FCM_2_AbaReq 0;
BA_ "ASIL" SG_ 325 FCM_2_AbaLvl 2;
BA_ "GenSigSendType" SG_ 325 FCM_2_AbaLvl 0;
BA_ "ASIL" SG_ 325 FCM_2_Avl 2;
BA_ "GenSigSendType" SG_ 325 FCM_2_Avl 0;
BA_ "GenSigSendType" SG_ 330 FCM_3_CRC1 0;
BA_ "GenSigSendType" SG_ 330 FCM_3_RollgCntr1 0;
BA_ "GenSigSendType" SG_ 330 FCM_3_Resd1 0;
BA_ "GenSigInvalidValue" SG_ 330 FCM_3_PilotkBrkDecTar 4095;
BA_ "GenSigStartValue" SG_ 330 FCM_3_PilotkBrkDecTar 2000;
BA_ "ASIL" SG_ 330 FCM_3_PilotkBrkDecTar 2;
BA_ "GenSigSendType" SG_ 330 FCM_3_PilotkBrkDecTar 0;
BA_ "ASIL" SG_ 330 FCM_3_PilotCtrlType 2;
BA_ "GenSigSendType" SG_ 330 FCM_3_PilotCtrlType 0;
BA_ "ASIL" SG_ 330 FCM_3_PilotParkCtrlRepSta 2;
BA_ "GenSigSendType" SG_ 330 FCM_3_PilotParkCtrlRepSta 0;
BA_ "ASIL" SG_ 330 FCM_3_PilotBrkDecTarVld 2;
BA_ "GenSigSendType" SG_ 330 FCM_3_PilotBrkDecTarVld 0;
BA_ "ASIL" SG_ 330 FCM_3_PilotBrkDecTarReq 2;
BA_ "GenSigSendType" SG_ 330 FCM_3_PilotBrkDecTarReq 0;
BA_ "ASIL" SG_ 330 FCM_3_PilotDec2StpReq 2;
BA_ "GenSigSendType" SG_ 330 FCM_3_PilotDec2StpReq 0;
BA_ "ASIL" SG_ 330 FCM_3_PilotDriOffReq 2;
BA_ "GenSigSendType" SG_ 330 FCM_3_PilotDriOffReq 0;
BA_ "GenSigSendType" SG_ 335 ONEBOX_5_CRC1 0;
BA_ "GenSigSendType" SG_ 335 ONEBOX_5_RollgCntr1 0;
BA_ "GenSigSendType" SG_ 335 ONEBOX_5_Resd1 0;
BA_ "ASIL" SG_ 335 ONEBOX_5_PilotParkBrkDecCtlAvl 2;
BA_ "GenSigSendType" SG_ 335 ONEBOX_5_PilotParkBrkDecCtlAvl 0;
BA_ "GenSigStartValue" SG_ 335 ONEBOX_5_PilotParkBrkDecActSts 1;
BA_ "ASIL" SG_ 335 ONEBOX_5_PilotParkBrkDecActSts 2;
BA_ "GenSigSendType" SG_ 335 ONEBOX_5_PilotParkBrkDecActSts 0;
BA_ "ASIL" SG_ 335 ONEBOX_5_CddAdcActiveVehHld 2;
BA_ "GenSigSendType" SG_ 335 ONEBOX_5_CddAdcActiveVehHld 0;
BA_ "ASIL" SG_ 335 ONEBOX_5_APCFailureSts 2;
BA_ "GenSigSendType" SG_ 335 ONEBOX_5_APCFailureSts 0;
BA_ "ASIL" SG_ 335 ONEBOX_5_APCStatus 2;
BA_ "GenSigSendType" SG_ 335 ONEBOX_5_APCStatus 0;
BA_ "ASIL" SG_ 335 ONEBOX_5_ApaAvl 2;
BA_ "GenSigSendType" SG_ 335 ONEBOX_5_ApaAvl 0;
BA_ "ASIL" SG_ 335 ONEBOX_5_RpaAvl 2;
BA_ "GenSigSendType" SG_ 335 ONEBOX_5_RpaAvl 0;
BA_ "ASIL" SG_ 335 ONEBOX_5_MebAvl 2;
BA_ "GenSigSendType" SG_ 335 ONEBOX_5_MebAvl 0;
BA_ "ASIL" SG_ 335 ONEBOX_5_CddApActiveVehHld 2;
BA_ "GenSigSendType" SG_ 335 ONEBOX_5_CddApActiveVehHld 0;
BA_ "GenSigInvalidValue" SG_ 335 ONEBOX_5_SysBrkP 1023;
BA_ "ASIL" SG_ 335 ONEBOX_5_SysBrkP 2;
BA_ "GenSigSendType" SG_ 335 ONEBOX_5_SysBrkP 0;
BA_ "ASIL" SG_ 335 ONEBOX_5_SysBrkPVld 2;
BA_ "GenSigSendType" SG_ 335 ONEBOX_5_SysBrkPVld 0;
BA_ "ASIL" SG_ 335 ONEBOX_5_AbpActSts 2;
BA_ "GenSigSendType" SG_ 335 ONEBOX_5_AbpActSts 0;
BA_ "ASIL" SG_ 335 ONEBOX_5_AbpAvlSts 2;
BA_ "GenSigSendType" SG_ 335 ONEBOX_5_AbpAvlSts 0;
BA_ "ASIL" SG_ 335 ONEBOX_5_AwbActSts 2;
BA_ "GenSigSendType" SG_ 335 ONEBOX_5_AwbActSts 0;
BA_ "ASIL" SG_ 335 ONEBOX_5_AwbAvlSts 2;
BA_ "GenSigSendType" SG_ 335 ONEBOX_5_AwbAvlSts 0;
BA_ "ASIL" SG_ 335 ONEBOX_5_AbaActSts 2;
BA_ "GenSigSendType" SG_ 335 ONEBOX_5_AbaActSts 0;
BA_ "ASIL" SG_ 335 ONEBOX_5_AbaAvlSts 2;
BA_ "GenSigSendType" SG_ 335 ONEBOX_5_AbaAvlSts 0;
BA_ "ASIL" SG_ 335 ONEBOX_5_AbaLvlSts 2;
BA_ "GenSigSendType" SG_ 335 ONEBOX_5_AbaLvlSts 0;
BA_ "GenSigSendType" SG_ 335 ONEBOX_5_CRC2 0;
BA_ "GenSigSendType" SG_ 335 ONEBOX_5_RollgCntr2 0;
BA_ "GenSigSendType" SG_ 335 ONEBOX_5_Resd2 0;
BA_ "GenSigSendType" SG_ 335 ONEBOX_5_OPDHydAvalible 0;
BA_ "GenSigSendType" SG_ 335 ONEBOX_5_CoastRegenQualify_FA 0;
BA_ "GenSigSendType" SG_ 335 ONEBOX_5_OPDHydBrkActvCompenTqVD 0;
BA_ "GenSigSendType" SG_ 335 ONEBOX_5_OPDHoldStatus 0;
BA_ "GenSigSendType" SG_ 335 ONEBOX_5_VehicleStandstillValid 0;
BA_ "GenSigSendType" SG_ 335 ONEBOX_5_VehicleStandstill 0;
BA_ "GenSigStartValue" SG_ 335 ONEBOX_5_OPDHydBrkActvCompenTq 65535;
BA_ "GenSigSendType" SG_ 335 ONEBOX_5_OPDHydBrkActvCompenTq 0;
BA_ "GenSigStartValue" SG_ 335 ONEBOX_5_OmpEngTorqReq 32768;
BA_ "GenSigSendType" SG_ 335 ONEBOX_5_OmpEngTorqReq 0;
BA_ "GenSigSendType" SG_ 335 ONEBOX_5_OmpStatus 0;
BA_ "GenSigSendType" SG_ 335 ONEBOX_5_OmpEngTorqReqEna 0;
BA_ "GenSigSendType" SG_ 345 ADS_1_CRC1 0;
BA_ "GenSigSendType" SG_ 345 ADS_1_RollgCntr1 0;
BA_ "GenSigSendType" SG_ 345 ADS_1_Resd1 0;
BA_ "GenSigInvalidValue" SG_ 345 ADS_1_PilotParkBrkDecTar 4095;
BA_ "GenSigStartValue" SG_ 345 ADS_1_PilotParkBrkDecTar 2000;
BA_ "ASIL" SG_ 345 ADS_1_PilotParkBrkDecTar 2;
BA_ "GenSigSendType" SG_ 345 ADS_1_PilotParkBrkDecTar 0;
BA_ "ASIL" SG_ 345 ADS_1_PilotParkCtrlType 2;
BA_ "GenSigSendType" SG_ 345 ADS_1_PilotParkCtrlType 0;
BA_ "ASIL" SG_ 345 ADS_1_PilotCtrlRepSta 2;
BA_ "GenSigSendType" SG_ 345 ADS_1_PilotCtrlRepSta 0;
BA_ "ASIL" SG_ 345 ADS_1_PilotParkCtrlRepMod 2;
BA_ "GenSigSendType" SG_ 345 ADS_1_PilotParkCtrlRepMod 0;
BA_ "ASIL" SG_ 345 ADS_1_PilotParkBrkDecTarVld 2;
BA_ "GenSigSendType" SG_ 345 ADS_1_PilotParkBrkDecTarVld 0;
BA_ "ASIL" SG_ 345 ADS_1_PilotParkBrkDecTarEnable 2;
BA_ "GenSigSendType" SG_ 345 ADS_1_PilotParkBrkDecTarEnable 0;
BA_ "ASIL" SG_ 345 ADS_1_PilotParkDec2StpReq 2;
BA_ "GenSigSendType" SG_ 345 ADS_1_PilotParkDec2StpReq 0;
BA_ "ASIL" SG_ 345 ADS_1_PilotParkDriOffReq 2;
BA_ "GenSigSendType" SG_ 345 ADS_1_PilotParkDriOffReq 0;
BA_ "GenSigInvalidValue" SG_ 345 ADS_1_StopDist 65535;
BA_ "ASIL" SG_ 345 ADS_1_StopDist 2;
BA_ "GenSigSendType" SG_ 345 ADS_1_StopDist 0;
BA_ "ASIL" SG_ 345 ADS_1_ParkCtrlMod 2;
BA_ "GenSigSendType" SG_ 345 ADS_1_ParkCtrlMod 0;
BA_ "ASIL" SG_ 345 ADS_1_PreFillReq 2;
BA_ "GenSigSendType" SG_ 345 ADS_1_PreFillReq 0;
BA_ "ASIL" SG_ 345 ADS_EPBCtrlReqValid 2;
BA_ "GenSigSendType" SG_ 345 ADS_EPBCtrlReqValid 0;
BA_ "ASIL" SG_ 345 ADS_EPBCtrlReq 2;
BA_ "GenSigSendType" SG_ 345 ADS_EPBCtrlReq 0;
BA_ "GenSigSendType" SG_ 359 ADS_VCU_1_CRC1 0;
BA_ "GenSigSendType" SG_ 359 ADS_VCU_1_RollgCntr1 0;
BA_ "GenSigSendType" SG_ 359 ADS_VCU_1_Resd1 0;
BA_ "ASIL" SG_ 359 ADS_VCU_1_DrvTarTq 2;
BA_ "GenSigSendType" SG_ 359 ADS_VCU_1_DrvTarTq 0;
BA_ "ASIL" SG_ 359 ADS_VCU_1_DrvTarTqVld 2;
BA_ "GenSigSendType" SG_ 359 ADS_VCU_1_DrvTarTqVld 0;
BA_ "ASIL" SG_ 359 ADS_VCU_1_DrvCtrlReq 2;
BA_ "GenSigSendType" SG_ 359 ADS_VCU_1_DrvCtrlReq 0;
BA_ "ASIL" SG_ 359 ADS_VCU_1_CtrlReqMod 2;
BA_ "GenSigSendType" SG_ 359 ADS_VCU_1_CtrlReqMod 0;
BA_ "ASIL" SG_ 359 ADS_VCU_1_DrvTarTqEnable 2;
BA_ "GenSigSendType" SG_ 359 ADS_VCU_1_DrvTarTqEnable 0;
BA_ "GenSigSendType" SG_ 359 ADS_VCU_1_AMAPRequest 0;
BA_ "GenSigSendType" SG_ 359 ADS_VCU_1_AMAPRequestVld 0;
BA_ "ASIL" SG_ 359 ADS_VCU_1_ADCCAvl 2;
BA_ "GenSigSendType" SG_ 359 ADS_VCU_1_ADCCAvl 0;
BA_ "GenSigSendType" SG_ 359 ADS_VCU_1_AMAPTqLimitVld 0;
BA_ "GenSigSendType" SG_ 359 FCM_FRM2_ACCStartStopInfo_167h 0;
BA_ "GenSigSendType" SG_ 359 ADS_VCU_1_CRC2 0;
BA_ "GenSigSendType" SG_ 359 ADS_VCU_1_RollgCntr2 0;
BA_ "GenSigSendType" SG_ 359 ADS_VCU_1_Resd2 0;
BA_ "ASIL" SG_ 359 ADS_VCU_1_TarGearReq 2;
BA_ "GenSigSendType" SG_ 359 ADS_VCU_1_TarGearReq 0;
BA_ "ASIL" SG_ 359 ADS_VCU_1_TarGearReqVld 2;
BA_ "GenSigSendType" SG_ 359 ADS_VCU_1_TarGearReqVld 0;
BA_ "ASIL" SG_ 359 ADS_VCU_1_GearCtrlEnable 2;
BA_ "GenSigSendType" SG_ 359 ADS_VCU_1_GearCtrlEnable 0;
BA_ "GenSigSendType" SG_ 359 ADS_VCU_1_RpaPTReadyReq 0;
BA_ "GenSigSendType" SG_ 359 ADS_VCU_1_AMAPTqLimit 0;
BA_ "GenSigSendType" SG_ 363 ADS_CRC2_16Bh 0;
BA_ "GenSigSendType" SG_ 363 ADS_RollgCntr2_16Bh 0;
BA_ "GenSigSendType" SG_ 363 ADS_Resd2_16Bh 0;
BA_ "GenSigStartValue" SG_ 363 ADS_TarYawRate_16Bh 16384;
BA_ "GenSigSendType" SG_ 363 ADS_TarYawRate_16Bh 0;
BA_ "GenSigSendType" SG_ 364 ADS_CRC1_16Ch 0;
BA_ "GenSigSendType" SG_ 364 ADS_RollgCntr1_16Ch 0;
BA_ "GenSigSendType" SG_ 364 ADS_Resd1_16Ch 0;
BA_ "GenSigStartValue" SG_ 364 ADS_DrvTarTq_16Ch 32768;
BA_ "ASIL" SG_ 364 ADS_DrvTarTq_16Ch 4;
BA_ "GenSigSendType" SG_ 364 ADS_DrvTarTq_16Ch 0;
BA_ "GenSigInvalidValue" SG_ 364 ADS_LimTqFactorK_16Ch 1023;
BA_ "GenSigStartValue" SG_ 364 ADS_LimTqFactorK_16Ch 1000;
BA_ "GenSigSendType" SG_ 364 ADS_LimTqFactorK_16Ch 0;
BA_ "GenSigSendType" SG_ 364 ADS_LimTqEnable_16Ch 0;
BA_ "ASIL" SG_ 364 ADS_DrvTarTqMod_16Ch 1;
BA_ "GenSigSendType" SG_ 364 ADS_DrvTarTqMod_16Ch 0;
BA_ "ASIL" SG_ 364 ADS_DrvTarTqEna_16Ch 4;
BA_ "GenSigSendType" SG_ 364 ADS_DrvTarTqEna_16Ch 0;
BA_ "ASIL" SG_ 364 ADS_DrvTarTqVld_16Ch 4;
BA_ "GenSigSendType" SG_ 364 ADS_DrvTarTqVld_16Ch 0;
BA_ "GenSigStartValue" SG_ 364 ADS_Total_Ref_Torque_16Ch 32768;
BA_ "ASIL" SG_ 364 ADS_Total_Ref_Torque_16Ch 1;
BA_ "GenSigSendType" SG_ 364 ADS_Total_Ref_Torque_16Ch 0;
BA_ "GenSigSendType" SG_ 364 ADS_CRC2_16Ch 0;
BA_ "GenSigSendType" SG_ 364 ADS_RollgCntr2_16Ch 0;
BA_ "GenSigSendType" SG_ 364 ADS_Resd2_16Ch 0;
BA_ "ASIL" SG_ 364 ADS_FctSts_16Ch 2;
BA_ "GenSigSendType" SG_ 364 ADS_FctSts_16Ch 0;
BA_ "ASIL" SG_ 364 ADS_GearCtrlEna_16Ch 4;
BA_ "GenSigSendType" SG_ 364 ADS_GearCtrlEna_16Ch 0;
BA_ "ASIL" SG_ 364 ADS_TarGearReqVld_16Ch 4;
BA_ "GenSigSendType" SG_ 364 ADS_TarGearReqVld_16Ch 0;
BA_ "ASIL" SG_ 364 ADS_TarGearReq_16Ch 4;
BA_ "GenSigSendType" SG_ 364 ADS_TarGearReq_16Ch 0;
BA_ "ASIL" SG_ 364 ADS_RapidRespEna_16Ch 1;
BA_ "GenSigSendType" SG_ 364 ADS_RapidRespEna_16Ch 0;
BA_ "GenSigStartValue" SG_ 364 ADS_MotTarSpd_16Ch 32768;
BA_ "ASIL" SG_ 364 ADS_MotTarSpd_16Ch 4;
BA_ "GenSigSendType" SG_ 364 ADS_MotTarSpd_16Ch 0;
BA_ "GenSigStartValue" SG_ 364 ADS_MotTqLimMin_16Ch 255;
BA_ "GenSigSendType" SG_ 364 ADS_MotTqLimMin_16Ch 0;
BA_ "ASIL" SG_ 364 ADS_MotTarMod_16Ch 4;
BA_ "GenSigSendType" SG_ 364 ADS_MotTarMod_16Ch 0;
BA_ "ASIL" SG_ 364 ADS_MotCtrlTar_16Ch 4;
BA_ "GenSigSendType" SG_ 364 ADS_MotCtrlTar_16Ch 0;
BA_ "GenSigStartValue" SG_ 364 ADS_MotTqLimMax_16Ch 255;
BA_ "GenSigSendType" SG_ 364 ADS_MotTqLimMax_16Ch 0;
BA_ "ASIL" SG_ 364 ADS_MotSpdCtrlEna_16Ch 4;
BA_ "GenSigSendType" SG_ 364 ADS_MotSpdCtrlEna_16Ch 0;
BA_ "GenSigSendType" SG_ 364 ADS_CRC3_16Ch 0;
BA_ "GenSigSendType" SG_ 364 ADS_RollgCntr3_16Ch 0;
BA_ "GenSigSendType" SG_ 364 ADS_Resd3_16Ch 0;
BA_ "GenSigStartValue" SG_ 364 ADS_MotTqRateLimMin_16Ch 255;
BA_ "GenSigSendType" SG_ 364 ADS_MotTqRateLimMin_16Ch 0;
BA_ "GenSigStartValue" SG_ 364 ADS_MotTqRateLimMax_16Ch 255;
BA_ "GenSigSendType" SG_ 364 ADS_MotTqRateLimMax_16Ch 0;
BA_ "GenSigStartValue" SG_ 364 ADS_TqUnloadRate_16Ch 255;
BA_ "GenSigSendType" SG_ 364 ADS_TqUnloadRate_16Ch 0;
BA_ "ASIL" SG_ 364 ADS_TqUnloadEna_16Ch 2;
BA_ "GenSigSendType" SG_ 364 ADS_TqUnloadEna_16Ch 0;
BA_ "GenSigSendType" SG_ 364 ADS_TarYawRateVld_16Ch 0;
BA_ "ASIL" SG_ 364 ADS_MotTarSpdSvValid_16Ch 4;
BA_ "GenSigSendType" SG_ 364 ADS_MotTarSpdSvValid_16Ch 0;
BA_ "GenSigStartValue" SG_ 364 ADS_DrvTarYawMom_16Ch 32768;
BA_ "GenSigSendType" SG_ 364 ADS_DrvTarYawMom_16Ch 0;
BA_ "GenSigSendType" SG_ 364 ADS_CRC4_16Ch 0;
BA_ "GenSigSendType" SG_ 364 ADS_RollgCntr4_16Ch 0;
BA_ "GenSigSendType" SG_ 364 ADS_Resd4_16Ch 0;
BA_ "GenSigSendType" SG_ 364 ADS_OneMotorCtrlEn_16Ch 0;
BA_ "GenSigSendType" SG_ 364 ADS_UrgentSteerFlg_16Ch 0;
BA_ "GenSigSendType" SG_ 364 ADS_DrvYawMomCtrlEna_16Ch 0;
BA_ "GenSigSendType" SG_ 364 ADS_DrvTarYawMomVld_16Ch 0;
BA_ "GenSigSendType" SG_ 364 ADS_PwrOnOffReq_16Ch 0;
BA_ "GenSigStartValue" SG_ 364 ADS_MotorCtrlTqWhlFL_16Ch 32768;
BA_ "GenSigSendType" SG_ 364 ADS_MotorCtrlTqWhlFL_16Ch 0;
BA_ "GenSigStartValue" SG_ 364 ADS_MotorCtrlTqWhlFR_16Ch 32768;
BA_ "GenSigSendType" SG_ 364 ADS_MotorCtrlTqWhlFR_16Ch 0;
BA_ "GenSigSendType" SG_ 364 ADS_CRC5_16Ch 0;
BA_ "GenSigSendType" SG_ 364 ADS_RollgCntr5_16Ch 0;
BA_ "GenSigSendType" SG_ 364 ADS_Resd5_16Ch 0;
BA_ "GenSigStartValue" SG_ 364 ADS_MotorCtrlTqWhlRL_16Ch 32768;
BA_ "GenSigSendType" SG_ 364 ADS_MotorCtrlTqWhlRL_16Ch 0;
BA_ "GenSigStartValue" SG_ 364 ADS_MotorCtrlTqWhlRR_16Ch 32768;
BA_ "GenSigSendType" SG_ 364 ADS_MotorCtrlTqWhlRR_16Ch 0;
BA_ "GenSigSendType" SG_ 364 ADS_CRC6_16Ch 0;
BA_ "GenSigSendType" SG_ 364 ADS_RollgCntr6_16Ch 0;
BA_ "GenSigSendType" SG_ 364 ADS_Resd6_16Ch 0;
BA_ "GenSigSendType" SG_ 444 ADS_CRC1_1BCh 0;
BA_ "GenSigSendType" SG_ 444 ADS_RollgCntr1 0;
BA_ "GenSigSendType" SG_ 444 ADS_Resd1_1BCh 0;
BA_ "GenSigSendType" SG_ 444 ADS_CRC2_1BCh 0;
BA_ "GenSigSendType" SG_ 444 ADS_RollgCntr2_1BCh 0;
BA_ "GenSigSendType" SG_ 444 ADS_Resd2_1BCh 0;
BA_ "ASIL" SG_ 444 APA_DrvTarTqVld_1BCh 2;
BA_ "GenSigSendType" SG_ 444 APA_DrvTarTqVld_1BCh 0;
BA_ "GenSigInvalidValue" SG_ 444 DrvTarTq_1BCh 65535;
BA_ "ASIL" SG_ 444 DrvTarTq_1BCh 2;
BA_ "GenSigSendType" SG_ 444 DrvTarTq_1BCh 0;
BA_ "ASIL" SG_ 444 APA_EPBCtrlReq_1BCh 2;
BA_ "GenSigSendType" SG_ 444 APA_EPBCtrlReq_1BCh 0;
BA_ "ASIL" SG_ 444 APA_DrvCtrlReq_1BCh 2;
BA_ "GenSigSendType" SG_ 444 APA_DrvCtrlReq_1BCh 0;
BA_ "ASIL" SG_ 444 APA_CtrlReqMod_1BCh 2;
BA_ "GenSigSendType" SG_ 444 APA_CtrlReqMod_1BCh 0;
BA_ "GenSigSendType" SG_ 444 APA_AMAPTqLimit_1BCh 0;
BA_ "ASIL" SG_ 444 APA_TarGearReqVld_1BCh 2;
BA_ "GenSigSendType" SG_ 444 APA_TarGearReqVld_1BCh 0;
BA_ "ASIL" SG_ 444 APA_TarGearReq_1BCh 2;
BA_ "GenSigSendType" SG_ 444 APA_TarGearReq_1BCh 0;
BA_ "GenSigSendType" SG_ 444 APA_AMAPTqLimitVld_1BCh 0;
BA_ "GenSigSendType" SG_ 444 APA_CRC3_1BCh 0;
BA_ "GenSigSendType" SG_ 444 APA_RollgCntr3_1BCh 0;
BA_ "GenSigSendType" SG_ 444 APA_Resd3_1BCh 0;
BA_ "GenSigSendType" SG_ 444 APA_TarSpd_1BCh 0;
BA_ "ASIL" SG_ 444 APA_ParkCtrlMod_1BCh 2;
BA_ "GenSigSendType" SG_ 444 APA_ParkCtrlMod_1BCh 0;
BA_ "ASIL" SG_ 444 APA_GearCtrlEnable_1BCh 2;
BA_ "GenSigSendType" SG_ 444 APA_GearCtrlEnable_1BCh 0;
BA_ "ASIL" SG_ 444 APA_EPBCtrlReqValid_1BCh 2;
BA_ "GenSigSendType" SG_ 444 APA_EPBCtrlReqValid_1BCh 0;
BA_ "ASIL" SG_ 444 APA_ADCCAvl_1BCh 2;
BA_ "GenSigSendType" SG_ 444 APA_ADCCAvl_1BCh 0;
BA_ "GenSigSendType" SG_ 444 APA_AMAPRequestVld_1BCh 0;
BA_ "GenSigSendType" SG_ 444 APA_AMAPRequest_1BCh 0;
BA_ "ASIL" SG_ 444 APA_DrvTarTqEnable_1BCh 2;
BA_ "GenSigSendType" SG_ 444 APA_DrvTarTqEnable_1BCh 0;
VAL_ 33 ACU_3_SCMRequest 0 "No crash" 1 "Front Crash" 2 "Side Crash" 3 "Rear Crash" 4 "Roll Crash" 5 "reserved" 6 "reserved" 7 "reserved";
VAL_ 33 ACU_3_LongitudinalAccelerationVD 0 "Valid" 1 "Reserved" 2 "Invalid" 3 "Initialize";
VAL_ 33 ACU_3_CrashOutputSts 0 "No crash" 16 "Rear Crash" 32 "Roll Crash" 1 "Belt Crash" 2 "Front Crash" 4 "Left Side Crash" 8 "Right Side Crash";
VAL_ 49 ACU_2_YASCalibrationSts 0 "Sensor  Not Calibrated" 1 "Sensor  Calibrated";
VAL_ 49 ACU_2_YawrateSigValidData 0 "Valid" 1 "Reserved" 2 "Invalid" 3 "Initialize";
VAL_ 49 ACU_2_LateralAccelerationSigVD 0 "Valid" 1 "Reserved" 2 "Invalid" 3 "Initialize";
VAL_ 56 VCU_10_ShiftInProgress 0 "Not in progress" 1 "In progress";
VAL_ 56 VCU_10_ShiftInProgressValidData 0 "Not Valid" 1 "V alid";
VAL_ 56 VCU_10_TargetGear 0 "No Request" 1 "Target gear P" 2 "Target gear R" 3 "Target gear N" 4 "Target gear D" 5 "Reserved" 6 "Reserved" 7 "Invalid";
VAL_ 56 VCU_10_ActualGear 0 "No Request" 1 "gear P" 2 "gear R" 3 "gear N" 4 "gear D" 5 "Reserved" 6 "Reserved" 7 "Invalid";
VAL_ 56 VCU_10_TargetGearValidData 0 "Not Valid" 1 "V alid";
VAL_ 56 VCU_10_ActualGearValidData 0 "Not Valid" 1 "V alid";
VAL_ 56 VCU_10_BrakePedalStsValidData 0 "Valid" 1 "Not Valid";
VAL_ 56 VCU_10_BrakePedalSts 0 "Not applied" 1 "Applied";
VAL_ 56 VCU_10_TowingMode 0 "NotActive" 1 "Active" 2 "Reserved" 3 "Reserved";
VAL_ 56 HCU_TCUR_GearShiftProgFlag 0 "No shift" 1 "Shift in processing" 2 "Shift success" 3 "Shift failed";
VAL_ 59 VCU_11_ActWheelSpdFA 65535 "Invalid";
VAL_ 59 VCU_11_IndcdDriverReqWhlTqStsFA 0 "no failure" 1 "failure";
VAL_ 59 VCU_11_ActWheelTorqueStsFA 0 "no failure" 1 "failure";
VAL_ 59 VCU_11_ActWheelSpdStsFA 0 "no failure" 1 "failure";
VAL_ 59 VCU_11_MotorReadyFMCU 0 "Not Ready" 1 "Ready";
VAL_ 59 VCU_11_ActWheelSpdRA 65535 "Invalid";
VAL_ 59 VCU_11_IndcdDriverReqWhlTqStsRA 0 "no failure" 1 "failure";
VAL_ 59 VCU_11_ActWheelTorqueStsRA 0 "no failure" 1 "failure";
VAL_ 59 VCU_11_MotorReadyRMCU 0 "Not Ready" 1 "Ready";
VAL_ 59 VCU_11_ActWheelSpdStsRA 0 "no failure" 1 "failure";
VAL_ 59 VCU_11_MbRegenMaxWheelQualifier 0 "NotIntialized" 1 "Normal" 2 "Faulty" 3 "Reserved";
VAL_ 59 VCU_11_MbRegenWheelQualifier 0 "NotIntialized" 1 "Normal" 2 "Faulty" 3 "Reserved";
VAL_ 59 VCU_11_EPBReq 0 "no request" 1 "Release" 2 "Close";
VAL_ 59 VCU_11_GasPedalPosInvalidData 0 "Valid" 1 "Invalid";
VAL_ 59 VCU_11_AcceleratorPosRawIVD 0 "Valid" 1 "Invalid";
VAL_ 59 VCU_11_GasPedalPosition 1023 "Invalid";
VAL_ 59 VCU_11_AcceleratorPosRaw 1023 "Invalid";
VAL_ 59 VCU_11_EPBReqValid 0 "Valid" 1 "Invalid";
VAL_ 59 VCU_11_CoastRegenTargetWheelFAQ 0 "NotIntialized" 1 "Normal" 2 "Faulty" 3 "Reserved";
VAL_ 59 VCU_11_CoastRegenTargetWheelRAQ 0 "NotIntialized" 1 "Normal" 2 "Faulty" 3 "Reserved";
VAL_ 59 VCU_11_OPDHoldRequest 0 "No request" 1 "Hold request" 2 "Drive off(Reserved)" 3 "Reserved";
VAL_ 59 VCU_11_OPDHydBrkCompenRqSts 0 "No request" 1 "Request hydraulic compensation";
VAL_ 59 VCU_11_OnePedalstatus 0 "OFF" 1 "ON";
VAL_ 59 HCU_11_RearWheelDir 0 "Undefinable" 1 "Forward" 2 "Backward" 3 "Reserved";
VAL_ 59 VCU_11_DrivingModReq 0 "Normal" 1 "Snow" 2 "Mud" 3 "Sand" 4 "Rock" 5 "Wade" 6 "Expert" 7 "UTURN" 8 "DRIFT" 9 "OffroadRace" 10 "DCM" 11 "Reserved" 12 "Reserved" 13 "Reserved" 14 "Reserved" 15 "Reserved" 16 "Reserved" 17 "Reserved" 18 "Reserved" 19 "Reserved" 20 "Reserved" 21 "Reserved" 22 "Reserved" 23 "Reserved" 24 "Reserved" 25 "Reserved" 26 "Reserved" 27 "Reserved" 28 "Reserved" 29 "Reserved" 30 "Reserved" 31 "Reserved";
VAL_ 75 VCU_12_VehWhlActTqVld 0 "no failure" 1 "failure";
VAL_ 75 VCU_12_DrvrGearIntervention 0 "No Intervention" 1 "Intervention";
VAL_ 75 VCU_12_PtTqActvSts 0 "Not response" 1 "Responsed";
VAL_ 75 VCU_12_PtTqAvl 0 "not available" 1 "available" 2 "available degraded" 3 "fault";
VAL_ 75 VCU_12_DrvrAccrPedlOvrd 0 "Not override" 1 "Override";
VAL_ 75 VCU_12_DrvrAccrPedlOvrdInVD 0 "Valid" 1 "Invalid";
VAL_ 75 HCU_12_PtTqMinVld 0 "no failure" 1 "failure";
VAL_ 75 TargetGearTransInp 0 "Disengage_Gear" 1 "Gear_1" 2 "Gear_2" 3 "Gear_3";
VAL_ 75 VCU_12_GasPedalInhabition 0 "Not Intervention" 1 "Intervention";
VAL_ 75 VCU_12_PtTqMaxVld 0 "no failure" 1 "failure";
VAL_ 75 HCU_26_TargetGearEM2 0 "Disengage gear" 1 "Gear 1" 2 "Gear 2" 3 "Gear 3";
VAL_ 75 VCU_12_VehWhlActTqADSVld 0 "no failure" 1 "failure";
VAL_ 152 ABS_ESP_1_ABSFailSts 0 "Not present" 1 "Fail present (lamp on)";
VAL_ 152 ABS_ESP_1_EBDFailSts 0 "Not present" 1 "Fail present (lamp on)";
VAL_ 152 ESP1_VehicleSpeedVSOSigValidData 0 "Valid" 1 "Not Valid";
VAL_ 152 IPB_SimulatorPressureSts 0 "Valid" 1 "Not Valid";
VAL_ 152 ABS_ESP_1_ABSActive 0 "Not active" 1 "Active";
VAL_ 152 ABS_ESP_1_VDCFailSts 0 "Not present" 1 "Fail present (lamp on)";
VAL_ 152 ABS_ESP_1_VDCActive 0 "Not active" 1 "Active";
VAL_ 152 ABS_ESP_1_TCSFailSts 0 "Not present" 1 "Fail present (lamp on)";
VAL_ 152 ABS_ESP_1_TCSActive 0 "Not active" 1 "Active";
VAL_ 152 BrakeSystemType 0 "ABS" 1 "ESP";
VAL_ 152 ABS_ESP_1_HHCFailSts 0 "Not present" 1 "Fail present (lamp on)";
VAL_ 152 ONEBOX_1_HHCActive 0 "Not active" 1 "Active";
VAL_ 152 ABS_ESP_1_HDCCtrlSts 0 "OFF" 1 "Not active braking(lamp on)" 2 "active braking(lamp flash)" 3 "Not Used";
VAL_ 152 ABS_ESP_1_HDCFailSts 0 "Not present" 1 "Fail present (lamp on)";
VAL_ 152 ONEBOX_1_HLRequest 0 "Not illuminate" 1 "Illuminate";
VAL_ 152 ABS_ESP_1_ESPSwitchStatus 0 "On" 1 "Disable";
VAL_ 152 ONEBOX_1_BLRequestController 0 "Not illuminate" 1 "Illuminate";
VAL_ 152 SwitchOffCruiseControl 0 "Not switch off cruise control" 1 "Switch off cruise control";
VAL_ 152 IPB_1_MbRegenTargetWheelQ 0 "NotIntialized" 1 "Normal" 2 "Faulty" 3 "Reserved";
VAL_ 152 ONEBOX_1_AEBdecActive 0 "Not active" 1 "Active";
VAL_ 152 ONEBOX_1_AEBdecAvailable 0 "Not available" 1 "Available";
VAL_ 152 ONEBOX_1_CDPActive 0 "Not active" 1 "Active";
VAL_ 152 Reserve_EPBStatus 0 "Released" 1 "Applied" 2 "Releasing" 3 "Applying" 4 "Unknown" 5 "ErrorApplied" 6 "Not Used" 7 "Not Used";
VAL_ 152 ONEBOX_1_CDPFailSts 0 "Fail not present" 1 "Fail present (lamp on)";
VAL_ 168 LHFWheelSpeedValidData_0A8h 0 "Valid" 1 "Not Valid";
VAL_ 168 RHFWheelSpeedValidData_0A8h 0 "Valid" 1 "Not Valid";
VAL_ 168 LHRWheelSpeedValidData_0A8h 0 "Valid" 1 "Not Valid";
VAL_ 168 RHRWheelSpeedValidData_0A8h 0 "Valid" 1 "Not Valid";
VAL_ 168 RHFWheelSpeedRPMValidData 0 "Valid" 1 "Not Valid";
VAL_ 168 LHFWheelSpeedRPMValidData 0 "Valid" 1 "Not Valid";
VAL_ 168 RHFWheelDriveDirection_0A8h 0 "Init" 1 "Forward" 2 "Backward" 3 "Stop" 4 "Invalid" 5 "reserved" 6 "reserved" 7 "reserved";
VAL_ 168 LHFWheelDriveDirection_0A8h 0 "Init" 1 "Forward" 2 "Backward" 3 "Stop" 4 "Invalid" 5 "reserved" 6 "reserved" 7 "reserved";
VAL_ 168 RHRWheelSpeedRPMValidData 0 "Valid" 1 "Not Valid";
VAL_ 168 LHRWheelSpeedRPMValidData 0 "Valid" 1 "Not Valid";
VAL_ 168 RHRWheelDriveDirection_0A8h 0 "Init" 1 "Forward" 2 "Backward" 3 "Stop" 4 "Invalid" 5 "reserved" 6 "reserved" 7 "reserved";
VAL_ 168 LHRWheelDriveDirection_0A8h 0 "Init" 1 "Forward" 2 "Backward" 3 "Stop" 4 "Invalid" 5 "reserved" 6 "reserved" 7 "reserved";
VAL_ 265 ONEBOX_AebBrkTqAvl_109h 0 "not available" 1 "available";
VAL_ 265 ONEBOX_AebBrkTqActv_109h 0 "NotActive" 1 "Active";
VAL_ 265 ONEBOX_DrvrBrkOvrdVld_109h 0 "Invalid" 1 "Valid";
VAL_ 265 ONEBOX_DrvrBrkOvrd_109h 0 "Not override" 1 "Override" 2 "Reserved" 3 "Reserved";
VAL_ 306 SAM_1_SteeringAngleSpeedVD 0 "Valid" 1 "Not Valid";
VAL_ 306 SAM_1_SteeringAngleVD 0 "Valid" 1 "Not Valid";
VAL_ 306 SAM_1_SASCalibrated 0 "Not calibrated" 1 "Calibrated";
VAL_ 306 SAM_1_SASInit 0 "Not Initialized" 1 "Initialized";
VAL_ 306 SAM_1_CANWarning 0 "No Warning" 1 "Warning";
VAL_ 306 SAM_1_InternalFailure 0 "No Failure" 1 "Failure";
VAL_ 306 SAM_1_BatteryWarning 0 "No Warning" 1 "Warning";
VAL_ 306 SAM_1_AngleFailure 0 "No Failure" 1 "Failure";
VAL_ 321 GearShiftPos 0 "POS_ZERO (Z)" 1 "POS_ONE (Z)(Manual position)" 2 "POS_TWO (forward twice / X2)" 3 "POS_THREE (forward once / X1)" 4 "POS_FOUR (backwards once / Y1)" 5 "POS_FIVE (backwards twice / Y2)" 6 "Tip+(manual shift up)" 7 "Tip-(manual shift down)" 8 "Shifter not initialized / INIT" 9 "Reserved" 10 "Reserved" 11 "Reserved" 12 "Reserved" 13 "Reserved" 14 "Reserved" 15 "SNA(Double fault shifter sensor)";
VAL_ 321 GearShiftPosInverse 0 "SNA(Double fault shifter sensor)" 1 "Reserved" 2 "Reserved" 3 "Reserved" 4 "Reserved" 5 "Reserved" 6 "Reserved" 7 "Shifter not initialized / INIT" 8 "Tip-(manual shift down)" 9 "Tip+(manual shift up)" 10 "POS_FIVE (backwards twice / Y2)" 11 "POS_FOUR (backwards once / Y1)" 12 "POS_THREE (forward once / X1)" 13 "POS_TWO (forward twice / X2)" 14 "POS_ONE (Z)(Manual position)" 15 "POS_ZERO (Z)";
VAL_ 321 STAT_ParkButton 0 "no request" 1 "driver request park button" 2 "Park button fault" 3 "reserved";
VAL_ 321 STAT_ShifterLeverFault 0 "Shift sensors both ok" 1 "Shift sensor 1 fault" 2 "Shift sensor 2 fault" 3 "Shift sensors both fault" 4 "Reserve" 5 "Reserve" 6 "Reserve" 7 "Invalid";
VAL_ 321 DriveModeActive 0 "Normal Mode" 1 "Sport Mode Active" 2 "Reserve" 3 "Invalid";
VAL_ 321 DriveModeReq 0 "Sport Mode Button Unpressed" 1 "Sport Mode Button Pressed" 2 "Reserve" 3 "Invalid";
VAL_ 325 FCM_2_AebTarDec 4095 "Invalid";
VAL_ 325 FCM_2_AebReqTyp 0 "No Request" 1 "Request" 2 "Reserved" 3 "Reserved";
VAL_ 325 FCM_2_AebTarDecVld 0 "Invalid" 1 "Valid";
VAL_ 325 FCM_2_AwbReq 0 "No Request" 1 "Request";
VAL_ 325 FCM_2_AwbLvl 0 "No Level" 1 "Level1" 2 "Level2" 3 "Level3";
VAL_ 325 FCM_2_BrkPreFillReq 0 "No Request" 1 "Request";
VAL_ 325 FCM_2_AbaReq 0 "No Request" 1 "Request";
VAL_ 325 FCM_2_AbaLvl 0 "No Level" 1 "Level1" 2 "Level2" 3 "Level3";
VAL_ 325 FCM_2_Avl 0 "Not available" 1 "Available";
VAL_ 330 FCM_3_PilotkBrkDecTar 4095 "Invalid";
VAL_ 330 FCM_3_PilotCtrlType 0 "comfortable" 1 "emergency";
VAL_ 330 FCM_3_PilotParkCtrlRepSta 0 "No Request" 1 "L12" 2 "reserved" 3 "reserved";
VAL_ 330 FCM_3_PilotBrkDecTarVld 0 "Invalid" 1 "Valid";
VAL_ 330 FCM_3_PilotBrkDecTarReq 0 "No request" 1 "Request";
VAL_ 330 FCM_3_PilotDec2StpReq 0 "No Request" 1 "Request";
VAL_ 330 FCM_3_PilotDriOffReq 0 "No Request" 1 "Request";
VAL_ 335 ONEBOX_5_PilotParkBrkDecCtlAvl 0 "Valid" 1 "Not valid";
VAL_ 335 ONEBOX_5_PilotParkBrkDecActSts 0 "Not active" 1 "Active L12" 2 "reserved" 3 "reserved";
VAL_ 335 ONEBOX_5_CddAdcActiveVehHld 0 "False" 1 "True";
VAL_ 335 ONEBOX_5_APCFailureSts 0 "no error" 1 "APC1(APA) driver not present" 2 "APC24(RPA AVP)  too high slope" 3 "too high speed" 4 "unexpect EPB Apply" 5 "reserved" 6 "VehicleBlock" 7 "Error" 8 "APC24(RPA AVP) trigger without secure";
VAL_ 335 ONEBOX_5_APCStatus 0 "Not Active" 1 "APA" 2 "RPA" 3 "AVP/HPA_VPA" 4 "MEB" 5 "Reserved" 6 "Reserved" 7 "Reserved";
VAL_ 335 ONEBOX_5_ApaAvl 0 "Not available" 1 "Available";
VAL_ 335 ONEBOX_5_RpaAvl 0 "Not available" 1 "Available";
VAL_ 335 ONEBOX_5_MebAvl 0 "Not available" 1 "Available";
VAL_ 335 ONEBOX_5_CddApActiveVehHld 0 "False" 1 "True";
VAL_ 335 ONEBOX_5_SysBrkPVld 0 "Not available" 1 "Available";
VAL_ 335 ONEBOX_5_AbpActSts 0 "Not active" 1 "Active";
VAL_ 335 ONEBOX_5_AbpAvlSts 0 "Not available" 1 "Available";
VAL_ 335 ONEBOX_5_AwbActSts 0 "Not active" 1 "Active";
VAL_ 335 ONEBOX_5_AwbAvlSts 0 "Not available" 1 "Available";
VAL_ 335 ONEBOX_5_AbaActSts 0 "Not active" 1 "Active";
VAL_ 335 ONEBOX_5_AbaAvlSts 0 "Not available" 1 "Available";
VAL_ 335 ONEBOX_5_AbaLvlSts 0 "No level" 1 "Level1" 2 "Level2" 3 "Level3";
VAL_ 335 ONEBOX_5_OPDHydAvalible 0 "Not Available" 1 "Available";
VAL_ 335 ONEBOX_5_CoastRegenQualify_FA 0 "OFF" 1 "ON" 2 "On without StabilityControl";
VAL_ 335 ONEBOX_5_OPDHydBrkActvCompenTqVD 0 "Invalid" 1 "Valid";
VAL_ 335 ONEBOX_5_OPDHoldStatus 0 "Not hold" 1 "Hold";
VAL_ 335 ONEBOX_5_VehicleStandstillValid 0 "Invalid" 1 "Valid";
VAL_ 335 ONEBOX_5_VehicleStandstill 0 "Not standstill" 1 "Standstill";
VAL_ 335 ONEBOX_5_OmpStatus 0 "Not Ready" 1 "Ready" 2 "Active" 3 "Reserved";
VAL_ 335 ONEBOX_5_OmpEngTorqReqEna 0 "No Request" 1 "Request";
VAL_ 345 ADS_1_PilotParkCtrlType 0 "comfortable" 1 "emergency";
VAL_ 345 ADS_1_PilotCtrlRepSta 0 "No Request" 1 "L12" 2 "reserved" 3 "reserved";
VAL_ 345 ADS_1_PilotParkCtrlRepMod 0 "No Request" 1 "Pilot Mode" 2 "Park Mode" 3 "reserved";
VAL_ 345 ADS_1_PilotParkBrkDecTarVld 0 "Invalid" 1 "Valid";
VAL_ 345 ADS_1_PilotParkBrkDecTarEnable 0 "Disable" 1 "Enable";
VAL_ 345 ADS_1_PilotParkDec2StpReq 0 "No Request" 1 "Request";
VAL_ 345 ADS_1_PilotParkDriOffReq 0 "No Request" 1 "Request";
VAL_ 345 ADS_1_ParkCtrlMod 0 "None" 1 "APA/RA" 2 "RPA" 3 "AVP/HPA_VPA" 4 "MEB" 5 "Reserved" 6 "Reserved" 7 "Reserved";
VAL_ 345 ADS_1_PreFillReq 0 "No Request" 1 "Request";
VAL_ 345 ADS_EPBCtrlReqValid 0 "Valid" 1 "Invalid";
VAL_ 345 ADS_EPBCtrlReq 0 "No Request" 1 "Lock" 2 "Release" 3 "Reserved";
VAL_ 359 ADS_VCU_1_DrvTarTqVld 0 "Invalid" 1 "Valid";
VAL_ 359 ADS_VCU_1_DrvCtrlReq 0 "No Req" 1 "Req" 2 "Reserved" 3 "Reserved";
VAL_ 359 ADS_VCU_1_CtrlReqMod 0 "No Request" 1 "Pilot Mode" 2 "Park Mode" 3 "MRM";
VAL_ 359 ADS_VCU_1_DrvTarTqEnable 0 "disenable" 1 "enable";
VAL_ 359 ADS_VCU_1_AMAPRequest 0 "No Request" 1 "Request";
VAL_ 359 ADS_VCU_1_AMAPRequestVld 0 "Invalid" 1 "Valid";
VAL_ 359 ADS_VCU_1_ADCCAvl 0 "Not available" 1 "Available";
VAL_ 359 ADS_VCU_1_AMAPTqLimitVld 0 "Invalid" 1 "Valid";
VAL_ 359 FCM_FRM2_ACCStartStopInfo_167h 0 "ACC_StopAllowed" 1 "ACC_StopForbidden" 2 "ACC_StartRequest" 3 "ACC_SystemFailure";
VAL_ 359 ADS_VCU_1_TarGearReq 0 "No request" 1 "P" 2 "R" 3 "N" 4 "D" 5 "Reserved" 6 "Reserved" 7 "Reserved";
VAL_ 359 ADS_VCU_1_TarGearReqVld 0 "Invalid" 1 "Valid";
VAL_ 359 ADS_VCU_1_GearCtrlEnable 0 "Enable" 1 "Disable";
VAL_ 359 ADS_VCU_1_RpaPTReadyReq 0 "No request" 1 "Request";
VAL_ 364 ADS_LimTqEnable_16Ch 0 "disable" 1 "enable";
VAL_ 364 ADS_DrvTarTqMod_16Ch 0 "油门override模式" 1 "油门抑制模式" 2 "Reserved" 3 "Reserved";
VAL_ 364 ADS_DrvTarTqEna_16Ch 0 "disable" 1 "enable";
VAL_ 364 ADS_DrvTarTqVld_16Ch 0 "Invalid" 1 "Valid" 2 "Reserved" 3 "Reserved";
VAL_ 364 ADS_FctSts_16Ch 0 "Off" 1 "On";
VAL_ 364 ADS_GearCtrlEna_16Ch 0 "disable" 1 "enable";
VAL_ 364 ADS_TarGearReqVld_16Ch 0 "Invalid" 1 "Valid" 2 "Reserved" 3 "Reserved";
VAL_ 364 ADS_TarGearReq_16Ch 0 "No request" 1 "P档" 2 "R档" 3 "N档" 4 "D档" 5 "Reserved" 6 "Reserved" 7 "Reserved";
VAL_ 364 ADS_RapidRespEna_16Ch 0 "disable" 1 "enable";
VAL_ 364 ADS_MotTarMod_16Ch 0 "扭矩模式" 1 "转速模式" 2 "SV模式" 3 "reserved";
VAL_ 364 ADS_MotCtrlTar_16Ch 0 "FL" 1 "RL" 2 "FL + RL" 3 "RL + RR" 4 "reserved" 5 "reserved" 6 "reserved" 7 "reserved";
VAL_ 364 ADS_MotSpdCtrlEna_16Ch 0 "Disable" 1 "Enable";
VAL_ 364 ADS_TqUnloadEna_16Ch 0 "Disable" 1 "Enable" 2 "Reserved" 3 "Reserved";
VAL_ 364 ADS_TarYawRateVld_16Ch 0 "Invalid" 1 "Valid";
VAL_ 364 ADS_MotTarSpdSvValid_16Ch 0 "invalid" 1 "valid";
VAL_ 364 ADS_OneMotorCtrlEn_16Ch 0 "Disable（总扭矩请求）" 1 "Enable（单电机扭矩请求）" 2 "reserved" 3 "reserved";
VAL_ 364 ADS_UrgentSteerFlg_16Ch 0 "Disable" 1 "Enable";
VAL_ 364 ADS_DrvYawMomCtrlEna_16Ch 0 "Disable" 1 "Enable";
VAL_ 364 ADS_DrvTarYawMomVld_16Ch 0 "Invalid" 1 "Valid";
VAL_ 364 ADS_PwrOnOffReq_16Ch 0 "no request" 1 "Power on 上电（从OFF至整车Ready状态）" 2 "Power off 下电（KL15 OFF)" 3 "上Ready（等同于过动力防盗）" 4 "下Ready（等同于退动力防盗，需维持高压）" 5 "reserved" 6 "reserved" 7 "reserved";
VAL_ 444 APA_DrvTarTqVld_1BCh 0 "Invalid" 1 "Valid";
VAL_ 444 APA_EPBCtrlReq_1BCh 0 "No Request" 1 "Lock" 2 "Release" 3 "Reserved";
VAL_ 444 APA_DrvCtrlReq_1BCh 0 "No Req" 1 "Req" 2 "Reserved" 3 "Reserved";
VAL_ 444 APA_CtrlReqMod_1BCh 0 "No Request" 1 "Pilot Mode" 2 "Park Mode" 3 "MRM";
VAL_ 444 APA_TarGearReqVld_1BCh 0 "Invalid" 1 "Valid";
VAL_ 444 APA_TarGearReq_1BCh 0 "No request" 1 "P" 2 "R" 3 "N" 4 "D" 5 "Reserved" 6 "Reserved" 7 "Reserved";
VAL_ 444 APA_AMAPTqLimitVld_1BCh 0 "Invalid" 1 "Valid";
VAL_ 444 APA_ParkCtrlMod_1BCh 0 "None" 1 "APA/RA" 2 "RPA" 3 "AVP/HPA_VPA" 4 "MEB" 5 "Reserved" 6 "Reserved" 7 "Reserved";
VAL_ 444 APA_GearCtrlEnable_1BCh 0 "Enable" 1 "Disable";
VAL_ 444 APA_EPBCtrlReqValid_1BCh 0 "Valid" 1 "Invalid";
VAL_ 444 APA_ADCCAvl_1BCh 0 "Not available" 1 "Available";
VAL_ 444 APA_AMAPRequestVld_1BCh 0 "Invalid" 1 "Valid";
VAL_ 444 APA_AMAPRequest_1BCh 0 "No Request" 1 "Request";
VAL_ 444 APA_DrvTarTqEnable_1BCh 0 "disenable" 1 "enable";
